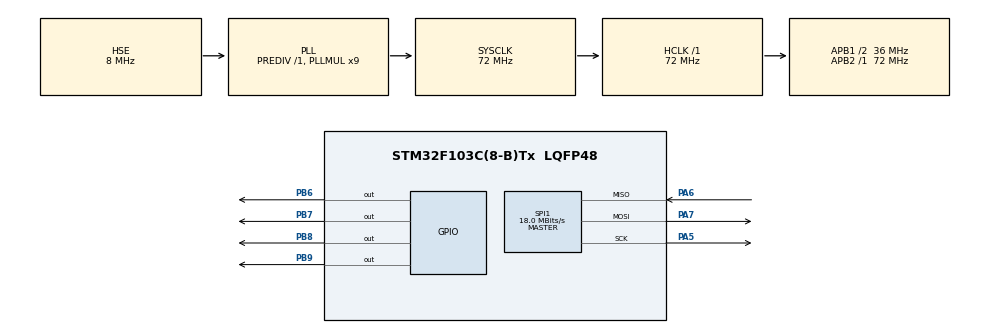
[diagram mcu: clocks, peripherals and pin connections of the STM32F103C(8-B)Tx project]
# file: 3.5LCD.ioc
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Mcu.Family=STM32F1
Mcu.Name=STM32F103C(8-B)Tx
Mcu.Package=LQFP48
NVIC.PriorityGroup=NVIC_PRIORITYGROUP_4
PA13.Mode=Serial_Wire
PA13.Signal=SYS_JTMS-SWDIO
PA14.Mode=Serial_Wire
PA14.Signal=SYS_JTCK-SWCLK
PA5.Mode=Full_Duplex_Master
PA5.Signal=SPI1_SCK
PA6.Mode=Full_Duplex_Master
PA6.Signal=SPI1_MISO
PA7.Mode=Full_Duplex_Master
PA7.Signal=SPI1_MOSI
PB6.GPIO_Speed=GPIO_SPEED_FREQ_HIGH
PB6.Signal=GPIO_Output
PB7.GPIO_Speed=GPIO_SPEED_FREQ_HIGH
PB7.Signal=GPIO_Output
PB8.GPIO_Speed=GPIO_SPEED_FREQ_HIGH
PB8.PinState=GPIO_PIN_RESET
PB8.Signal=GPIO_Output
PB9.GPIO_Speed=GPIO_SPEED_FREQ_HIGH
PB9.PinState=GPIO_PIN_SET
PB9.Signal=GPIO_Output
PD0-OSC_IN.Mode=HSE-External-Oscillator
PD0-OSC_IN.Signal=RCC_OSC_IN
PD1-OSC_OUT.Mode=HSE-External-Oscillator
PD1-OSC_OUT.Signal=RCC_OSC_OUT
ProjectManager.HeapSize=0x200
ProjectManager.StackSize=0x400
ProjectManager.TargetToolchain=MDK-ARM V5.32
RCC.AHBFreq_Value=72000000
RCC.APB1CLKDivider=RCC_HCLK_DIV2
RCC.APB1Freq_Value=36000000
RCC.APB1TimFreq_Value=72000000
RCC.APB2Freq_Value=72000000
RCC.APB2TimFreq_Value=72000000
RCC.HCLKFreq_Value=72000000
RCC.PLLMUL=RCC_PLL_MUL9
RCC.PLLSourceVirtual=RCC_PLLSOURCE_HSE
RCC.SYSCLKFreq_VALUE=72000000
RCC.SYSCLKSource=RCC_SYSCLKSOURCE_PLLCLK
RCC.USBFreq_Value=72000000
SPI1.BaudRatePrescaler=SPI_BAUDRATEPRESCALER_4
SPI1.CLKPhase=SPI_PHASE_2EDGE
SPI1.CLKPolarity=SPI_POLARITY_HIGH
SPI1.CRCCalculation=SPI_CRCCALCULATION_DISABLE
SPI1.CalculateBaudRate=18.0 MBits/s
SPI1.DataSize=SPI_DATASIZE_16BIT
SPI1.Direction=SPI_DIRECTION_2LINES
SPI1.Mode=SPI_MODE_MASTER
SPI1.VirtualType=VM_MASTER
board=custom

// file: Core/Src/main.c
/* USER CODE BEGIN Header */
/**
  ******************************************************************************
  * @file           : main.c
  * @brief          : Main program body
  ******************************************************************************
  * @attention
  *
  * Copyright (c) 2025 STMicroelectronics.
  * All rights reserved.
  *
  * This software is licensed under terms that can be found in the LICENSE file
  * in the root directory of this software component.
  * If no LICENSE file comes with this software, it is provided AS-IS.
  *
  ******************************************************************************
  */
/* USER CODE END Header */
#include "main.h"
#include "spi.h"
#include "gpio.h"

/* USER CODE BEGIN Includes */
#include "lcd.h"
/* USER CODE END Includes */

/* USER CODE BEGIN PTD */
uint8_t BMP[] =
{
/*--  ������һ��ͼ��C:\Users\Administrator\Desktop\22.bmp  --*/
/*--  ���x�߶�=240x160  --*/
0x00,0x00,0x00,0x00,0x00,0x00,0x00,0x00,0x00,0x00,0x00,0x00,0x00,0x00,0x00,0x00,
0x00,0x00,0x00,0x00,0x00,0x00,0x00,0x00,0x00,0x00,0x00,0x00,0x00,0x00,0x00,0x00,
0x00,0x00,0x00,0x00,0x00,0x00,0x00,0x00,0x00,0x00,0x00,0x00,0x00,0x00,0x00,0x00,
0x00,0x00,0x00,0x00,0x00,0x00,0x00,0x00,0x00,0x00,0x00,0x00,0x00,0x00,0x00,0x00,
0x00,0x00,0x00,0x00,0x00,0x00,0x00,0x00,0x00,0x00,0x00,0x00,0x00,0x00,0x00,0x00,
0x00,0x00,0x00,0x00,0x00,0x00,0x00,0x00,0x00,0x00,0x00,0x00,0x00,0x00,0x00,0x00,
0x00,0x00,0x00,0x00,0x00,0x00,0x00,0x00,0x00,0x00,0x00,0x00,0x00,0x00,0x00,0x00,
0x00,0x00,0x00,0x00,0x00,0x00,0x00,0x00,0x00,0x00,0x00,0x00,0x00,0x00,0x00,0x00,
0x00,0x00,0x00,0x00,0x00,0x00,0x00,0x00,0x00,0x00,0x00,0x00,0x00,0x00,0x00,0x00,
0x00,0x00,0x00,0x00,0x00,0x00,0x00,0x00,0x00,0x00,0x00,0x00,0x00,0x00,0x00,0x00,
0x00,0x00,0x00,0x00,0x00,0x00,0x00,0x00,0x00,0x00,0x00,0x00,0x00,0x00,0x00,0x00,
0x00,0x00,0x00,0x00,0x00,0x00,0x00,0x00,0x00,0x00,0x00,0x00,0x00,0x00,0x00,0x00,
0x00,0x00,0x00,0x00,0x00,0x00,0x00,0x00,0x00,0x00,0x00,0x00,0x00,0x00,0x00,0x00,
0x00,0x00,0x00,0x00,0x00,0x00,0x00,0x00,0x00,0x00,0x00,0x00,0x00,0x00,0x00,0x00,
0x00,0x00,0x00,0x00,0x00,0x00,0x00,0x00,0x00,0x00,0x00,0x00,0x00,0x00,0x00,0x00,
0x00,0x00,0x00,0x00,0x00,0x00,0x00,0x00,0x00,0x00,0x00,0x00,0x00,0x00,0x00,0x00,
0x00,0x00,0x00,0x00,0x00,0x00,0x00,0x00,0x00,0x00,0x00,0x00,0x00,0x00,0x00,0x00,
0x00,0x00,0x00,0x00,0x00,0x00,0x00,0x00,0x00,0x00,0x00,0x00,0x00,0x00,0x00,0x00,
0x00,0x00,0x00,0x00,0x00,0x00,0x00,0x00,0x00,0x00,0x00,0x00,0x00,0x00,0x00,0x00,
0x00,0x00,0x00,0x00,0x00,0x00,0x00,0x00,0x00,0x00,0x00,0x00,0x00,0x00,0x00,0x00,
0x00,0x00,0x00,0x00,0x00,0x00,0x00,0x00,0x00,0x00,0x00,0x00,0x00,0x00,0x00,0x00,
0x00,0x00,0x00,0x00,0x00,0x00,0x00,0x00,0x00,0x00,0x00,0x00,0x00,0x00,0x00,0x00,
0x00,0x00,0x00,0x00,0x00,0x00,0x00,0x00,0x00,0x00,0x00,0x00,0x00,0x00,0x00,0x00,
0x00,0x00,0x00,0x00,0x00,0x00,0x00,0x00,0x00,0x00,0x00,0x00,0x00,0x00,0x00,0x00,
0x00,0x00,0x00,0x00,0x00,0x00,0x00,0x00,0x00,0x00,0x00,0x00,0x00,0x00,0x00,0x00,
0x00,0x00,0x00,0x00,0x00,0x00,0x00,0x00,0x00,0x00,0x00,0x00,0x00,0x00,0x00,0x00,
0x00,0x00,0x00,0x00,0x00,0x00,0x00,0x00,0x00,0x00,0x00,0x00,0x00,0x00,0x00,0x00,
0x00,0x00,0x00,0x00,0x00,0x00,0x00,0x00,0x00,0x00,0x00,0x00,0x00,0x00,0x00,0x00,
0x00,0x00,0x00,0x00,0x00,0x00,0x00,0x00,0x00,0x00,0x00,0x00,0x00,0x00,0x00,0x00,
0x00,0x00,0x00,0x00,0x00,0x00,0x00,0x00,0x00,0x00,0x00,0x00,0x00,0x00,0x00,0x00,
0x00,0x00,0x00,0x00,0x00,0x00,0x00,0x00,0x00,0x00,0x00,0x00,0x00,0x00,0x00,0x00,
0x00,0x00,0x00,0x00,0x00,0x00,0x00,0x00,0x00,0x00,0x00,0x00,0x00,0x00,0x00,0x00,
0x00,0x00,0x00,0x00,0x00,0x00,0x00,0x00,0x00,0x00,0x00,0x00,0x00,0x00,0x00,0x00,
0x00,0x00,0x00,0x00,0x00,0x00,0x00,0x00,0x00,0x00,0x00,0x00,0x00,0x00,0x00,0x00,
0x00,0x00,0x00,0x00,0x00,0x00,0x00,0x00,0x00,0x00,0x00,0x00,0x00,0x00,0x00,0x00,
0x00,0x00,0x00,0x00,0x00,0x00,0x00,0x00,0x00,0x00,0x00,0x00,0x00,0x00,0x00,0x00,
0x00,0x00,0x00,0x00,0x00,0x00,0x00,0x00,0x00,0x00,0x00,0x00,0x00,0x00,0x00,0x00,
0x00,0x00,0x00,0x00,0x00,0x00,0x00,0x00,0x00,0x00,0x00,0x00,0x00,0x00,0x00,0x00,
0x00,0x00,0x00,0x00,0x00,0x00,0x00,0x00,0x00,0x00,0x00,0x00,0x00,0x00,0x00,0x00,
0x00,0x00,0x00,0x00,0x00,0x00,0x00,0x00,0x00,0x00,0x00,0x00,0x00,0x00,0x00,0x00,
0x00,0x00,0x00,0x00,0x00,0x00,0x00,0x00,0x00,0x00,0x00,0x00,0x00,0x00,0x00,0x00,
0x00,0x00,0x00,0x00,0x00,0x00,0x00,0x00,0x00,0x00,0x00,0x00,0x00,0x00,0x00,0x00,
0x00,0x00,0x00,0x00,0x00,0x00,0x00,0x00,0x00,0x00,0x00,0x00,0x00,0x00,0x00,0x00,
0x00,0x00,0x00,0x00,0x00,0x00,0x00,0x00,0x00,0x00,0x00,0x00,0x00,0x00,0x00,0x00,
0x00,0x00,0x00,0x00,0x00,0x00,0x00,0x00,0x00,0x00,0x00,0x00,0x00,0x00,0x00,0x00,
0x00,0x00,0x00,0x00,0x00,0x00,0x00,0x00,0x00,0x00,0x00,0x00,0x00,0x00,0x00,0x00,
0x00,0x00,0x00,0x00,0x00,0x00,0x00,0x00,0x00,0x00,0x00,0x00,0x00,0x00,0x00,0x00,
0x00,0x00,0x00,0x00,0x00,0x00,0x00,0x00,0x00,0x00,0x00,0x00,0x00,0x00,0x00,0x00,
0x00,0x00,0x00,0x00,0x00,0x00,0x00,0x00,0x00,0x00,0x00,0x00,0x00,0x00,0x00,0x00,
0x00,0x00,0x00,0x00,0x00,0x00,0x00,0x00,0x00,0x00,0x00,0x00,0x00,0x00,0x00,0x00,
0x00,0x00,0x00,0x00,0x00,0x00,0x00,0x00,0x00,0x00,0x00,0x00,0x00,0x00,0x00,0x00,
0x00,0x00,0x00,0x00,0x00,0x00,0x00,0x00,0x00,0x00,0x00,0x00,0x00,0x00,0x00,0x00,
0x00,0x00,0x00,0x00,0x00,0x00,0x00,0x00,0x00,0x00,0x00,0x00,0x00,0x00,0x00,0x00,
0x00,0x00,0x00,0x00,0x00,0x00,0x00,0x00,0x00,0x00,0x00,0x00,0x00,0x00,0x00,0x00,
0x00,0x00,0x00,0x00,0x00,0x00,0x00,0x00,0x00,0x00,0x00,0x00,0x00,0x00,0x00,0x00,
0x00,0x00,0x00,0x00,0x00,0x00,0x00,0x00,0x00,0x00,0x00,0x00,0x00,0x00,0x00,0x00,
0x00,0x00,0x00,0x00,0x00,0x00,0x00,0x00,0x00,0x00,0x00,0x00,0x00,0x00,0x00,0x00,
0x00,0x00,0x00,0x00,0x00,0x00,0x00,0x00,0x00,0x00,0x00,0x00,0x00,0x00,0x00,0x00,
0x00,0x00,0x00,0x00,0x00,0x00,0x00,0x00,0x00,0x00,0x00,0x00,0x00,0x00,0x00,0x00,
0x00,0x00,0x00,0x00,0x00,0x00,0x00,0x00,0x00,0x00,0x00,0x00,0x00,0x00,0x00,0x00,
0x00,0x00,0x00,0x00,0x00,0x00,0x00,0x00,0x00,0x00,0x00,0x00,0x00,0x00,0x00,0x00,
0x00,0x00,0x00,0x00,0x00,0x00,0x00,0x00,0x00,0x00,0x00,0x00,0x00,0x00,0x00,0x00,
0x00,0x00,0x00,0x00,0x00,0x00,0x00,0x00,0x00,0x00,0x00,0x00,0x00,0x00,0x00,0x00,
0x00,0x00,0x00,0x00,0x03,0xFF,0xC0,0x00,0x00,0x00,0x00,0x00,0x00,0x00,0x00,0x00,
0x00,0x00,0x00,0x0E,0x00,0x00,0x00,0x00,0x00,0x00,0x03,0xFF,0x00,0x03,0x80,0x00,
0x00,0x00,0x03,0xFF,0xC1,0xC0,0x00,0x00,0x00,0x00,0x00,0x00,0x00,0x00,0x00,0x00,
0x00,0x1F,0x00,0x00,0x00,0x00,0x00,0x00,0x03,0xFF,0x80,0x0F,0x80,0x00,0x00,0x00,
0x03,0xFF,0xC3,0xC0,0x00,0x00,0x00,0x00,0x00,0x00,0x00,0x00,0x00,0x00,0x00,0x3F,
0xC0,0x00,0x00,0x00,0x00,0x00,0x03,0xFF,0x80,0x1F,0xC0,0x00,0x00,0x00,0x03,0xFF,
0xCF,0xE0,0x00,0x00,0x00,0x00,0x00,0x00,0x00,0x00,0x00,0x00,0x00,0x7F,0xE0,0x7F,
0xFF,0xFF,0xFF,0x00,0x03,0xFF,0x80,0x7F,0xE0,0x00,0x00,0x00,0x03,0xFF,0xDF,0xF0,
0x00,0x00,0x00,0x00,0x00,0x00,0x00,0x00,0x00,0x00,0x00,0x7F,0xF0,0x7F,0xFF,0xFF,
0xFF,0x00,0x03,0xFF,0x81,0xFF,0xF0,0x00,0x00,0x00,0x03,0xFF,0xFF,0xF8,0x00,0x00,
0x00,0x00,0x00,0x00,0x00,0x00,0x00,0x00,0x00,0xFF,0xF8,0x7F,0xFF,0xFF,0xFF,0x00,
0x03,0xFF,0x81,0xFF,0xF0,0x00,0x00,0x00,0x03,0xFF,0xFF,0xFC,0x00,0x00,0x00,0x00,
0x00,0x00,0x00,0x00,0x00,0x00,0x01,0xFF,0xFE,0x7F,0xFF,0xFF,0xFF,0x3F,0xF3,0xFF,
0x81,0xFF,0xF8,0x00,0x00,0x00,0x03,0xFF,0xFF,0xFE,0x00,0x00,0x00,0x00,0x00,0x00,
0x00,0x00,0x00,0x00,0x01,0xFF,0xFF,0x7F,0xFF,0xFF,0xFF,0x3F,0xF3,0xFF,0x80,0xFF,
0xFC,0x00,0x00,0x00,0x03,0xFF,0xDF,0xFF,0x00,0x00,0x00,0x00,0x00,0x00,0x00,0x00,
0x00,0x00,0x00,0xFF,0xFF,0xFF,0xFF,0xFF,0xFF,0x3F,0xF3,0xFF,0x80,0x7F,0xFC,0x00,
0x00,0x00,0x03,0xFF,0xCF,0xFF,0x80,0x00,0x00,0x00,0x00,0x00,0x00,0x00,0x00,0x00,
0x00,0x7F,0xFF,0xFF,0xFF,0xFF,0xFF,0x3F,0xF3,0xFF,0x80,0x7F,0xFE,0x00,0x00,0x00,
0x03,0xFF,0xC7,0xFF,0x80,0x00,0x00,0x00,0x00,0x00,0x00,0x00,0x00,0x00,0x00,0x3F,
0xFF,0xFF,0xFF,0xFF,0xFF,0x3F,0xF3,0xFF,0x80,0x3F,0xFF,0x00,0x00,0x00,0x03,0xFF,
0xC7,0xFF,0x80,0x00,0x00,0x00,0x00,0x00,0x00,0x00,0x00,0x00,0x00,0x1F,0xFF,0xFF,
0xFF,0xFF,0xFF,0x3F,0xF3,0xFF,0x80,0x1F,0xFF,0x00,0x00,0x00,0x03,0xFF,0xC3,0xFF,
0x00,0x00,0x00,0x00,0x00,0x00,0x00,0x00,0x00,0x00,0x00,0x0F,0xFF,0x7F,0xC0,0x01,
0xFF,0x3F,0xF3,0xFF,0x80,0x1F,0xFF,0x80,0x00,0x00,0x03,0xFF,0xC1,0xFE,0x00,0x00,
0x00,0x00,0x00,0x00,0x00,0x00,0x00,0x00,0x00,0x07,0xFE,0x7F,0xC0,0x01,0xFF,0x3F,
0xF3,0xFF,0x80,0x0F,0xFF,0xC0,0x00,0x00,0x03,0xFF,0xC0,0xF8,0x00,0x00,0x00,0x00,
0x00,0x00,0x00,0x00,0x00,0x00,0x00,0x03,0xFC,0x7F,0xC0,0x01,0xFF,0x3F,0xF3,0xFF,
0x80,0x0F,0xFF,0xFF,0xFF,0xFF,0xFF,0xFF,0xFF,0xFF,0xE0,0x00,0x00,0x00,0x00,0x00,
0x00,0x00,0x00,0x00,0x00,0x01,0xF8,0x7F,0xC0,0x01,0xFF,0x3F,0xF3,0xFF,0x80,0x07,
0xFF,0xBF,0xFF,0xFF,0xFF,0xFF,0xFF,0xFF,0xE0,0x00,0x00,0x00,0x00,0x00,0x00,0x00,
0x00,0x00,0x00,0x00,0xF0,0x7F,0xC0,0x01,0xFF,0x3F,0xF3,0xFF,0x80,0x03,0xFE,0x3F,
0xFF,0xFF,0xFF,0xFF,0xFF,0xFF,0xE0,0x00,0x00,0x00,0x00,0x00,0x00,0x00,0x00,0x00,
0x00,0x00,0x60,0x7F,0xCF,0xF9,0xFF,0x3F,0xF3,0xFF,0x80,0x03,0xFC,0x3F,0xFF,0xFF,
0xFF,0xFF,0xFF,0xFF,0xE0,0x00,0x00,0x00,0x00,0x00,0x00,0x00,0x00,0x00,0x00,0x00,
0x00,0x7F,0xCF,0xF9,0xFF,0x3F,0xF3,0xFF,0x80,0x01,0xF0,0x3F,0xFF,0xFF,0xFF,0xFF,
0xFF,0xFF,0xE0,0x00,0x00,0x00,0x00,0x00,0x00,0x00,0x00,0x00,0x00,0x00,0x00,0x7F,
0xCF,0xF9,0xFF,0x3F,0xF3,0xFF,0x80,0x01,0xC0,0x3F,0xFF,0xFF,0xFF,0xFF,0xFF,0xFF,
0xE0,0x00,0x00,0x00,0x00,0x00,0x00,0x00,0x00,0x00,0x00,0x00,0x00,0x7F,0xCF,0xF9,
0xFF,0x3F,0xF3,0xFF,0x80,0x00,0x00,0x3F,0xFF,0xFF,0xFF,0xFF,0xFF,0xFF,0xE0,0x00,
0x00,0x00,0x00,0x00,0x00,0x00,0x00,0x00,0x00,0x3C,0x00,0x7F,0xCF,0xF9,0xFF,0x3F,
0xF3,0xFF,0x80,0x00,0x00,0x3F,0xFF,0xFF,0xFF,0xFF,0xFF,0xFF,0xE0,0x00,0x00,0x00,
0x00,0x00,0x00,0x00,0x00,0x00,0x00,0x7E,0x00,0x7F,0xCF,0xF9,0xFF,0x3F,0xF3,0xFF,
0x80,0x00,0x00,0x3F,0xFF,0xFF,0xFF,0xFF,0xFF,0xFF,0xE0,0x00,0x00,0x00,0x00,0x00,
0x00,0x00,0x00,0x00,0x00,0xFF,0x00,0x7F,0xCF,0xF9,0xFF,0x3F,0xF3,0xFF,0x80,0x00,
0x00,0x3F,0xFF,0xFF,0xFF,0xFF,0xFF,0xFF,0xE0,0x00,0x00,0x00,0x00,0x00,0x00,0x00,
0x00,0x00,0x01,0xFF,0x80,0x7F,0xCF,0xF9,0xFF,0x3F,0xF3,0xFF,0x8F,0xFF,0xFE,0x3F,
0xFF,0xFF,0xFF,0xFF,0xFF,0xFF,0xE0,0x00,0x00,0x00,0x00,0x00,0x00,0x00,0x00,0x00,
0x01,0xFF,0xE0,0x7F,0xCF,0xF9,0xFF,0x3F,0xF3,0xFF,0x8F,0xFF,0xFE,0x00,0x00,0x00,
0x01,0xFF,0xE0,0x00,0x00,0x00,0x00,0x00,0x00,0x00,0x00,0x00,0x00,0x00,0x03,0xFF,
0xF0,0x7F,0xCF,0xF9,0xFF,0x3F,0xF3,0xFF,0x8F,0xFF,0xFE,0x00,0x00,0x00,0x01,0xFF,
0xE0,0x00,0x00,0x00,0x00,0x00,0x00,0x00,0x00,0x00,0x00,0x00,0x07,0xFF,0xF8,0x7F,
0xCF,0xF9,0xFF,0x3F,0xF3,0xFF,0x8F,0xFF,0xFE,0x00,0x00,0x00,0x01,0xFF,0xE0,0x00,
0x00,0x00,0x00,0x00,0x00,0x00,0x00,0x00,0x00,0x00,0x07,0xFF,0xFC,0x7F,0xCF,0xF9,
0xFF,0x3F,0xF3,0xFF,0x8F,0xFF,0xFE,0x00,0x00,0x00,0x01,0xFF,0xE0,0x00,0x00,0x00,
0x00,0x00,0x00,0x00,0x00,0x00,0x00,0x00,0x03,0xFF,0xFE,0x7F,0xCF,0xF9,0xFF,0x3F,
0xF3,0xFF,0x8F,0xFF,0xFE,0x00,0x00,0x00,0x01,0xFF,0xE0,0x00,0x00,0x00,0x00,0x00,
0x00,0x00,0x00,0x00,0x00,0x00,0x01,0xFF,0xFF,0x7F,0xCF,0xF9,0xFF,0x3F,0xF3,0xFF,
0x8F,0xFF,0xFE,0x00,0x00,0x00,0x01,0xFF,0xE0,0x00,0x00,0x00,0x00,0x00,0x00,0x00,
0x00,0x00,0x00,0x00,0x00,0xFF,0xFF,0x7F,0xCF,0xF9,0xFF,0x3F,0xF3,0xFF,0x8F,0xFF,
0xFE,0x00,0x00,0x00,0x01,0xFF,0xE0,0x00,0x00,0x00,0x00,0x00,0x00,0x00,0x00,0x00,
0x00,0x00,0x00,0x7F,0xFE,0x7F,0xCF,0xF9,0xFF,0x3F,0xF3,0xFF,0x8F,0xFF,0xFE,0x00,
0x00,0x00,0x01,0xFF,0xE0,0x00,0x00,0x00,0x00,0x00,0x00,0x00,0x00,0x00,0x00,0x00,
0x00,0x3F,0xFC,0x7F,0xCF,0xF9,0xFF,0x3F,0xF3,0xFF,0x8F,0xFF,0xFE,0x1F,0xFF,0xFF,
0xFD,0xFF,0xE0,0x00,0x00,0x00,0x00,0x00,0x00,0x00,0x00,0x00,0x00,0x00,0x00,0x1F,
0xF8,0x7F,0xCF,0xF9,0xFF,0x3F,0xF3,0xFF,0x87,0xFF,0xFE,0x1F,0xFF,0xFF,0xFD,0xFF,
0xE0,0x00,0x00,0x00,0x00,0x00,0x00,0x00,0x00,0x00,0x00,0x00,0x00,0x0F,0xF0,0x7F,
0xCF,0xF9,0xFF,0x3F,0xF3,0xFF,0x80,0x1F,0xFE,0x1F,0xFF,0xFF,0xFD,0xFF,0xE0,0x00,
0x00,0x00,0x00,0x00,0x00,0x00,0x00,0x00,0x00,0x00,0x00,0x07,0xF0,0x7F,0xCF,0xF9,
0xFF,0x3F,0xF3,0xFF,0x80,0x1F,0xFE,0x1F,0xFF,0xFF,0xFD,0xFF,0xE0,0x00,0x00,0x00,
0x00,0x00,0x00,0x00,0x00,0x00,0x00,0x00,0x00,0x03,0xE0,0x7F,0xCF,0xF9,0xFF,0x3F,
0xF3,0xFF,0x80,0x1F,0xFE,0x1F,0xFF,0xFF,0xFD,0xFF,0xE0,0x00,0x00,0x00,0x00,0x00,
0x00,0x00,0x00,0x00,0x00,0x00,0x00,0x01,0xC0,0x7F,0xCF,0xF9,0xFF,0x3F,0xF3,0xFF,
0x80,0x1F,0xFE,0x1F,0xFF,0xFF,0xFD,0xFF,0xE0,0x00,0x00,0x00,0x00,0x00,0x00,0x00,
0x00,0x00,0x00,0x00,0x00,0x00,0x00,0x7F,0xCF,0xF9,0xFF,0x3F,0xF3,0xFF,0x80,0x1F,
0xFE,0x1F,0xFF,0xFF,0xFD,0xFF,0xE0,0x00,0x00,0x00,0x00,0x00,0x00,0x00,0x00,0x00,
0x00,0x00,0x00,0x00,0x00,0x7F,0xCF,0xF9,0xFF,0x3F,0xF3,0xFF,0x80,0x1F,0xFE,0x1F,
0xFF,0xFF,0xFD,0xFF,0xE0,0x00,0x00,0x00,0x00,0x00,0x00,0x00,0x00,0x00,0x00,0x00,
0x00,0x00,0x00,0x7F,0xCF,0xF9,0xFF,0x3F,0xF3,0xFF,0x80,0x1F,0xFE,0x1F,0xFF,0xFF,
0xFC,0xFF,0xF0,0x00,0x00,0x00,0x00,0x00,0x00,0x00,0x00,0x00,0x00,0x00,0x00,0x00,
0x00,0x7F,0xCF,0xF9,0xFF,0x3F,0xF3,0xFF,0x80,0x1F,0xFE,0x1F,0xFF,0xFF,0xFC,0xFF,
0xF0,0x00,0x00,0x00,0x00,0x00,0x00,0x00,0x00,0x00,0x00,0x00,0x00,0x07,0x00,0x7F,
0xCF,0xF1,0xFF,0x3F,0xF3,0xFF,0x80,0x1F,0xFE,0x0F,0xFF,0xFF,0xF8,0xFF,0xF0,0x00,
0x00,0x00,0x00,0x00,0x00,0x00,0x00,0x00,0x00,0x00,0x00,0x07,0xE0,0x7F,0xDF,0xF1,
0xFF,0x3F,0xF3,0xFF,0x80,0x1F,0xFE,0x00,0x1F,0xFC,0x00,0xFF,0xF0,0x00,0x00,0x00,
0x00,0x00,0x00,0x00,0x00,0x00,0x00,0x00,0x00,0x07,0xFC,0x7F,0xDF,0xF1,0xFF,0x3F,
0xF3,0xFF,0x80,0x1F,0xFE,0x00,0x1F,0xFC,0x00,0xFF,0xF0,0x00,0x00,0x00,0x00,0x00,
0x00,0x00,0x00,0x00,0x00,0x00,0x00,0x07,0xFF,0x7F,0xDF,0xF1,0xFF,0x3F,0xF3,0xFF,
0x80,0x1F,0xFE,0x00,0x1F,0xFC,0x00,0xFF,0xF0,0x00,0x00,0x00,0x00,0x00,0x00,0x00,
0x00,0x00,0x00,0x00,0x00,0x0F,0xFF,0x7F,0xDF,0xF1,0xFF,0x3F,0xF3,0xFF,0x80,0x1F,
0xFE,0x00,0x1F,0xFC,0x00,0xFF,0xF0,0x00,0x00,0x00,0x00,0x00,0x00,0x00,0x00,0x00,
0x00,0x00,0x00,0x0F,0xFF,0x7F,0xDF,0xF1,0xFF,0x3F,0xF3,0xFF,0x80,0x1F,0xFE,0x00,
0x1F,0xFC,0x00,0xFF,0xF0,0x00,0x00,0x00,0x00,0x00,0x00,0x00,0x00,0x00,0x00,0x00,
0x00,0x0F,0xFF,0x7F,0xFF,0xF1,0xFF,0x3F,0xF3,0xFF,0x80,0x1F,0xFE,0x00,0x1F,0xFC,
0x00,0xFF,0xF0,0x00,0x00,0x00,0x00,0x00,0x00,0x00,0x00,0x00,0x00,0x00,0x00,0x0F,
0xFF,0x7F,0xFF,0xF1,0xFF,0x3F,0xF3,0xFF,0x80,0x1F,0xFE,0x00,0x1F,0xFC,0x00,0xFF,
0xF8,0x00,0x00,0x00,0x00,0x00,0x00,0x00,0x00,0x00,0x00,0x00,0x00,0x0F,0xFE,0x7F,
0xFF,0xF1,0xFF,0x3F,0xF3,0xFF,0x80,0x1F,0xFE,0x00,0x1F,0xFC,0x00,0xFF,0xF8,0x00,
0x00,0x00,0x00,0x00,0x00,0x00,0x00,0x00,0x00,0x00,0x00,0x1F,0xFE,0x7F,0xFF,0xE0,
0x00,0x3F,0xF3,0xFF,0x80,0x1F,0xFE,0x0C,0x1F,0xFC,0x00,0x7F,0xF8,0x78,0x00,0x00,
0x00,0x00,0x00,0x00,0x00,0x00,0x00,0x00,0x00,0x1F,0xFE,0x00,0x7F,0xE0,0x00,0x3F,
0xF3,0xFF,0x80,0x1F,0xFE,0x3C,0x1F,0xFC,0x00,0x7F,0xF8,0x7E,0x00,0x00,0x00,0x00,
0x00,0x00,0x00,0x00,0x00,0x00,0x00,0x1F,0xFE,0x00,0x7F,0xE6,0x00,0x3F,0xF3,0xFF,
0x80,0x1F,0xFE,0x7E,0x1F,0xFC,0x00,0x7F,0xF8,0x7F,0xC0,0x00,0x00,0x00,0x00,0x00,
0x00,0x00,0x00,0x00,0x00,0x1F,0xFC,0x00,0xFF,0xEF,0x00,0x3F,0xF3,0xFF,0x80,0x1F,
0xFE,0xFE,0x1F,0xFC,0x00,0x7F,0xF8,0x7F,0xF0,0x00,0x00,0x00,0x00,0x00,0x00,0x00,
0x00,0x00,0x00,0x3F,0xFC,0x00,0xFF,0xFF,0x80,0x3F,0xF3,0xFF,0x80,0x1F,0xFF,0xFE,
0x1F,0xFC,0x00,0x7F,0xFC,0x7F,0xF0,0x00,0x00,0x00,0x00,0x00,0x00,0x00,0x00,0x00,
0x00,0x3F,0xFC,0x01,0xFF,0xFF,0xC0,0x3F,0xF3,0xFF,0x80,0x1F,0xFF,0xFE,0x1F,0xFC,
0x00,0x7F,0xFC,0x7F,0xF0,0x00,0x00,0x00,0x00,0x00,0x00,0x00,0x00,0x00,0x00,0x3F,
0xFC,0x03,0xFF,0xFF,0xE0,0x3F,0xF3,0xFF,0x80,0x1F,0xFF,0xFE,0x1F,0xFC,0x7F,0x7F,
0xFC,0x7F,0xF0,0x00,0x00,0x00,0x00,0x00,0x00,0x00,0x00,0x00,0x00,0x3F,0xF8,0x03,
0xFF,0xFF,0xF0,0x00,0x03,0xFF,0x80,0x1F,0xFF,0xFE,0x1F,0xFF,0xFF,0x3F,0xFC,0x7F,
0xE0,0x00,0x00,0x00,0x00,0x00,0x00,0x00,0x00,0x00,0x00,0x7F,0xF8,0x07,0xFF,0xFF,
0xF8,0x00,0x03,0xFF,0x80,0x1F,0xFF,0xFE,0x1F,0xFF,0xFF,0x3F,0xFC,0xFF,0xE0,0x00,
0x00,0x00,0x00,0x00,0x00,0x00,0x00,0x00,0x00,0x7F,0xF8,0x0F,0xFF,0x7F,0xFC,0x00,
0x03,0xFF,0x80,0x1F,0xFF,0xFF,0xFF,0xFF,0xFF,0x3F,0xFE,0xFF,0xE0,0x00,0x00,0x00,
0x00,0x00,0x00,0x00,0x00,0x00,0x00,0x7F,0xF8,0x1F,0xFF,0x3F,0xFE,0x00,0x03,0xFF,
0x80,0x1F,0xFF,0xFF,0xFF,0xFF,0xFF,0x3F,0xFE,0xFF,0xE0,0x00,0x00,0x00,0x00,0x00,
0x00,0x00,0x00,0x00,0x00,0x7F,0xF0,0x3F,0xFE,0x3F,0xFE,0x00,0x07,0xFF,0x80,0x1F,
0xFF,0xFF,0xFF,0xFF,0xFF,0x1F,0xFE,0xFF,0xE0,0x00,0x00,0x00,0x00,0x00,0x00,0x00,
0x00,0x00,0x00,0xFF,0xF0,0x7F,0xFE,0x1F,0xFF,0x3F,0xFF,0xFF,0x80,0x1F,0xFF,0xFF,
0xFF,0xFF,0xFF,0x1F,0xFF,0xFF,0xE0,0x00,0x00,0x00,0x00,0x00,0x00,0x00,0x00,0x00,
0x00,0xFF,0xF0,0xFF,0xFC,0x0F,0xFF,0x9F,0xFF,0xFF,0x80,0x1F,0xFF,0xFF,0xFF,0xFF,
0xFF,0x1F,0xFF,0xFF,0xC0,0x00,0x00,0x00,0x00,0x00,0x00,0x00,0x00,0x00,0x00,0xFF,
0xF3,0xFF,0xF8,0x07,0xFF,0xDF,0xFF,0xFF,0x80,0x3F,0xFF,0xFF,0xFF,0xFF,0xFF,0x1F,
0xFF,0xFF,0xC0,0x00,0x00,0x00,0x00,0x00,0x00,0x00,0x00,0x00,0x01,0xFF,0xE7,0xFF,
0xF8,0x07,0xFF,0xFF,0xFF,0xFF,0x00,0x3F,0xFF,0xFF,0xFF,0xFF,0xFF,0x0F,0xFF,0xFF,
0xC0,0x00,0x00,0x00,0x00,0x00,0x00,0x00,0x00,0x00,0x01,0xFF,0xE7,0xFF,0xF0,0x03,
0xFF,0xDF,0xFF,0xFF,0x00,0x7F,0xFF,0x9F,0xFF,0xFF,0xFF,0x0F,0xFF,0xFF,0xC0,0x00,
0x00,0x00,0x00,0x00,0x00,0x00,0x00,0x00,0x01,0xFF,0xE3,0xFF,0xE0,0x01,0xFF,0x8F,
0xFF,0xFF,0x00,0x3F,0xFF,0x1F,0xFF,0xFF,0xFC,0x0F,0xFF,0xFF,0x80,0x00,0x00,0x00,
0x00,0x00,0x00,0x00,0x00,0x00,0x01,0xFF,0xE3,0xFF,0xC0,0x00,0xFF,0x0F,0xFF,0xFF,
0x00,0x1F,0xFE,0x1F,0xFF,0xFE,0x00,0x07,0xFF,0xFF,0x80,0x00,0x00,0x00,0x00,0x00,
0x00,0x00,0x00,0x00,0x03,0xFF,0xC1,0xFF,0xC0,0x00,0xFC,0x0F,0xFF,0xFE,0x00,0x1F,
0xF8,0x1F,0xFF,0x80,0x00,0x07,0xFF,0xFF,0x00,0x00,0x00,0x00,0x00,0x00,0x00,0x00,
0x00,0x00,0x03,0xFF,0xC0,0xFF,0x80,0x00,0x78,0x0F,0xFF,0xFC,0x00,0x0F,0xF0,0x0F,
0xE0,0x00,0x00,0x03,0xFF,0xFF,0x00,0x00,0x00,0x00,0x00,0x00,0x00,0x00,0x00,0x00,
0x01,0xFF,0xC0,0x7F,0x00,0x00,0x30,0x0F,0xFF,0xF8,0x00,0x07,0xE0,0x00,0x00,0x00,
0x00,0x01,0xFF,0xFE,0x00,0x00,0x00,0x00,0x00,0x00,0x00,0x00,0x00,0x00,0x00,0x3F,
0xC0,0x3E,0x00,0x00,0x00,0x07,0xFF,0xF0,0x00,0x03,0xC0,0x00,0x00,0x00,0x00,0x00,
0xFF,0xFC,0x00,0x00,0x00,0x00,0x00,0x00,0x00,0x00,0x00,0x00,0x00,0x07,0x80,0x3C,
0x00,0x00,0x00,0x07,0xFF,0x00,0x00,0x03,0x80,0x00,0x00,0x00,0x00,0x00,0x7F,0xF8,
0x00,0x00,0x00,0x00,0x00,0x00,0x00,0x00,0x00,0x00,0x00,0x00,0x00,0x18,0x00,0x00,
0x00,0x00,0x00,0x00,0x00,0x00,0x00,0x00,0x00,0x00,0x00,0x00,0x1F,0xE0,0x00,0x00,
0x00,0x00,0x00,0x00,0x00,0x00,0x00,0x00,0x00,0x00,0x00,0x00,0x00,0x00,0x00,0x00,
0x00,0x00,0x00,0x00,0x00,0x00,0x00,0x00,0x00,0x00,0x00,0x00,0x00,0x00,0x00,0x00,
0x00,0x00,0x00,0x00,0x00,0x00,0x00,0x00,0x00,0x00,0x00,0x00,0x00,0x00,0x00,0x00,
0x00,0x00,0x00,0x00,0x00,0x00,0x00,0x00,0x00,0x00,0x00,0x00,0x00,0x00,0x00,0x00,
0x00,0x00,0x00,0x00,0x00,0x00,0x00,0x00,0x00,0x00,0x00,0x00,0x00,0x00,0x00,0x00,
0x00,0x00,0x00,0x00,0x00,0x00,0x00,0x00,0x00,0x00,0x00,0x00,0x00,0x00,0x00,0x00,
0x00,0x00,0x00,0x00,0x00,0x00,0x00,0x00,0x00,0x00,0x00,0x00,0x00,0x00,0x00,0x00,
0x00,0x00,0x00,0x00,0x00,0x00,0x00,0x00,0x00,0x00,0x00,0x00,0x00,0x00,0x00,0x00,
0x00,0x00,0x00,0x00,0x00,0x00,0x00,0x00,0x00,0x00,0x00,0x00,0x00,0x00,0x00,0x00,
0x00,0x00,0x00,0x00,0x00,0x00,0x00,0x00,0x00,0x00,0x00,0x00,0x00,0x00,0x00,0x00,
0x00,0x00,0x00,0x00,0x00,0x00,0x00,0x00,0x00,0x00,0x00,0x00,0x00,0x00,0x00,0x00,
0x00,0x00,0x00,0x00,0x00,0x00,0x00,0x00,0x00,0x00,0x00,0x00,0x00,0x00,0x00,0x00,
0x00,0x00,0x00,0x00,0x00,0x00,0x00,0x00,0x00,0x00,0x00,0x00,0x00,0x00,0x00,0x00,
0x00,0x00,0x00,0x00,0x00,0x00,0x00,0x00,0x00,0x00,0x00,0x00,0x00,0x00,0x00,0x00,
0x00,0x00,0x00,0x00,0x00,0x00,0x00,0x00,0x00,0x00,0x00,0x00,0x00,0x00,0x00,0x00,
0x00,0x00,0x00,0x00,0x00,0x00,0x00,0x00,0x00,0x00,0x00,0x00,0x00,0x00,0x00,0x00,
0x00,0x00,0x00,0x00,0x00,0x00,0x00,0x00,0x00,0x00,0x00,0x00,0x00,0x00,0x00,0x00,
0x00,0x00,0x00,0x00,0x00,0x00,0x00,0x00,0x00,0x00,0x00,0x00,0x00,0x00,0x00,0x00,
0x00,0x00,0x00,0x00,0x00,0x00,0x00,0x00,0x00,0x00,0x00,0x00,0x00,0x00,0x00,0x00,
0x00,0x00,0x00,0x00,0x00,0x00,0x00,0x00,0x00,0x00,0x00,0x00,0x00,0x00,0x00,0x00,
0x00,0x00,0x00,0x00,0x00,0x00,0x00,0x00,0x00,0x00,0x00,0x00,0x00,0x00,0x00,0x00,
0x00,0x00,0x00,0x00,0x00,0x00,0x00,0x00,0x00,0x00,0x00,0x00,0x00,0x00,0x00,0x00,
0x00,0x00,0x00,0x00,0x00,0x00,0x00,0x00,0x00,0x00,0x00,0x00,0x00,0x00,0x00,0x00,
0x00,0x00,0x00,0x00,0x00,0x00,0x00,0x00,0x00,0x00,0x00,0x00,0x00,0x00,0x00,0x00,
0x00,0x00,0x00,0x00,0x00,0x00,0x00,0x00,0x00,0x00,0x00,0x00,0x00,0x00,0x00,0x00,
0x00,0x00,0x00,0x00,0x00,0x00,0x00,0x00,0x00,0x00,0x00,0x00,0x00,0x00,0x00,0x00,
0x00,0x00,0x00,0x00,0x00,0x00,0x00,0x00,0x00,0x00,0x00,0x00,0x00,0x00,0x00,0x00,
0x00,0x00,0x00,0x00,0x00,0x00,0x00,0x00,0x00,0x00,0x00,0x00,0x00,0x00,0x00,0x00,
0x00,0x00,0x00,0x00,0x00,0x00,0x00,0x00,0x00,0x00,0x00,0x00,0x00,0x00,0x00,0x00,
0x00,0x00,0x00,0x00,0x00,0x00,0x00,0x00,0x00,0x00,0x00,0x00,0x00,0x00,0x00,0x00,
0x00,0x00,0x00,0x00,0x00,0x00,0x00,0x00,0x00,0x00,0x00,0x00,0x00,0x00,0x00,0x00,
0x00,0x00,0x00,0x00,0x00,0x00,0x00,0x00,0x00,0x00,0x00,0x00,0x00,0x00,0x00,0x00,
0x00,0x00,0x00,0x00,0x00,0x00,0x00,0x00,0x00,0x00,0x00,0x00,0x00,0x00,0x00,0x00,
0x00,0x00,0x00,0x00,0x00,0x00,0x00,0x00,0x00,0x00,0x00,0x00,0x00,0x00,0x00,0x00,
0x00,0x00,0x00,0x00,0x00,0x00,0x00,0x00,0x00,0x00,0x00,0x00,0x00,0x00,0x00,0x00,
0x00,0x00,0x00,0x00,0x00,0x00,0x00,0x00,0x00,0x00,0x00,0x00,0x00,0x00,0x00,0x00,
0x00,0x00,0x00,0x00,0x00,0x00,0x00,0x00,0x00,0x00,0x00,0x00,0x00,0x00,0x00,0x00,
0x00,0x00,0x00,0x00,0x00,0x00,0x00,0x00,0x00,0x00,0x00,0x00,0x00,0x00,0x00,0x00,
0x00,0x00,0x00,0x00,0x00,0x00,0x00,0x00,0x00,0x00,0x00,0x00,0x00,0x00,0x00,0x00,
0x00,0x00,0x00,0x00,0x00,0x00,0x00,0x00,0x00,0x00,0x00,0x00,0x00,0x00,0x00,0x00,
0x00,0x00,0x00,0x00,0x00,0x00,0x00,0x00,0x00,0x00,0x00,0x00,0x00,0x00,0x00,0x00,
0x00,0x00,0x00,0x00,0x00,0x00,0x00,0x00,0x00,0x00,0x00,0x00,0x00,0x00,0x00,0x00,
0x00,0x00,0x00,0x00,0x00,0x00,0x00,0x00,0x00,0x00,0x00,0x00,0x00,0x00,0x00,0x00,
0x00,0x00,0x00,0x00,0x00,0x00,0x00,0x00,0x00,0x00,0x00,0x00,0x00,0x00,0x00,0x00,
0x00,0x00,0x00,0x00,0x00,0x00,0x00,0x00,0x00,0x00,0x00,0x00,0x00,0x00,0x00,0x00,
0x00,0x00,0x00,0x00,0x00,0x00,0x00,0x00,0x00,0x00,0x00,0x00,0x00,0x00,0x00,0x00,
0x00,0x00,0x00,0x00,0x00,0x00,0x00,0x00,0x00,0x00,0x00,0x00,0x00,0x00,0x00,0x00,
0x00,0x00,0x00,0x00,0x00,0x00,0x00,0x00,0x00,0x00,0x00,0x00,0x00,0x00,0x00,0x00,
0x00,0x00,0x00,0x00,0x00,0x00,0x00,0x00,0x00,0x00,0x00,0x00,0x00,0x00,0x00,0x00,
0x00,0x00,0x00,0x00,0x00,0x00,0x00,0x00,0x00,0x00,0x00,0x00,0x00,0x00,0x00,0x00,
0x00,0x00,0x00,0x00,0x00,0x00,0x00,0x00,0x00,0x00,0x00,0x00,0x00,0x00,0x00,0x00,
0x00,0x00,0x00,0x00,0x00,0x00,0x00,0x00,0x00,0x00,0x00,0x00,0x00,0x00,0x00,0x00,
0x00,0x00,0x00,0x00,0x00,0x00,0x00,0x00,0x00,0x00,0x00,0x00,0x00,0x00,0x00,0x00,
0x00,0x00,0x00,0x00,0x00,0x00,0x00,0x00,0x00,0x00,0x00,0x00,0x00,0x00,0x00,0x00,
0x00,0x00,0x00,0x00,0x00,0x00,0x00,0x00,0x00,0x00,0x00,0x00,0x00,0x00,0x00,0x00,
0x00,0x00,0x00,0x00,0x00,0x00,0x00,0x00,0x00,0x00,0x00,0x00,0x00,0x00,0x00,0x00,
0x00,0x00,0x00,0x00,0x00,0x00,0x00,0x00,0x00,0x00,0x00,0x00,0x00,0x00,0x00,0x00,
0x00,0x00,0x00,0x00,0x00,0x00,0x00,0x00,0x00,0x00,0x00,0x00,0x00,0x00,0x00,0x00,
0x00,0x00,0x00,0x00,0x00,0x00,0x00,0x00,0x00,0x00,0x00,0x00,0x00,0x00,0x00,0x00,
0x00,0x00,0x00,0x00,0x00,0x00,0x00,0x00,0x00,0x00,0x00,0x00,0x00,0x00,0x00,0x00,
0x00,0x00,0x00,0x00,0x00,0x00,0x00,0x00,0x00,0x00,0x00,0x00,0x00,0x00,0x00,0x00,
0x00,0x00,0x00,0x00,0x00,0x00,0x00,0x00,0x00,0x00,0x00,0x00,0x00,0x00,0x00,0x00,
0x00,0x00,0x00,0x00,0x00,0x00,0x00,0x00,0x00,0x00,0x00,0x00,0x00,0x00,0x00,0x00,
0x00,0x00,0x00,0x00,0x00,0x00,0x00,0x00,0x00,0x00,0x00,0x00,0x00,0x00,0x00,0x00,
0x00,0x00,0x00,0x00,0x00,0x00,0x00,0x00,0x00,0x00,0x00,0x00,0x00,0x00,0x00,0x00,
0x00,0x00,0x00,0x00,0x00,0x00,0x00,0x00,0x00,0x00,0x00,0x00,0x00,0x00,0x00,0x00,
0x00,0x00,0x00,0x00,0x00,0x00,0x00,0x00,0x00,0x00,0x00,0x00,0x00,0x00,0x00,0x00,
0x00,0x00,0x00,0x00,0x00,0x00,0x00,0x00,0x00,0x00,0x00,0x00,0x00,0x00,0x00,0x00,
0x00,0x00,0x00,0x00,0x00,0x00,0x00,0x00,0x00,0x00,0x00,0x00,0x00,0x00,0x00,0x00,
0x00,0x00,0x00,0x00,0x00,0x00,0x00,0x00,0x00,0x00,0x00,0x00,0x00,0x00,0x00,0x00,
0x00,0x00,0x00,0x00,0x00,0x00,0x00,0x00,0x00,0x00,0x00,0x00,0x00,0x00,0x00,0x00,
0x00,0x00,0x00,0x00,0x00,0x00,0x00,0x00,0x00,0x00,0x00,0x00,0x00,0x00,0x00,0x00,
0x00,0x00,0x00,0x00,0x00,0x00,0x00,0x00,0x00,0x00,0x00,0x00,0x00,0x00,0x00,0x00,
0x00,0x00,0x00,0x00,0x00,0x00,0x00,0x00,0x00,0x00,0x00,0x00,0x00,0x00,0x00,0x00,
0x00,0x00,0x00,0x00,0x00,0x00,0x00,0x00,0x00,0x00,0x00,0x00,0x00,0x00,0x00,0x00,
0x00,0x00,0x00,0x00,0x00,0x00,0x00,0x00,0x00,0x00,0x00,0x00,0x00,0x00,0x00,0x00,
0x00,0x00,0x00,0x00,0x00,0x00,0x00,0x00,0x00,0x00,0x00,0x00,0x00,0x00,0x00,0x00,
0x00,0x00,0x00,0x00,0x00,0x00,0x00,0x00,0x00,0x00,0x00,0x00,0x00,0x00,0x00,0x00,
0x00,0x00,0x00,0x00,0x00,0x00,0x00,0x00,0x00,0x00,0x00,0x00,0x00,0x00,0x00,0x00,
0x00,0x00,0x00,0x00,0x00,0x00,0x00,0x00,0x00,0x00,0x00,0x00,0x00,0x00,0x00,0x00,
0x00,0x00,0x00,0x00,0x00,0x00,0x00,0x00,0x00,0x00,0x00,0x00,0x00,0x00,0x00,0x00,
0x00,0x00,0x00,0x00,0x00,0x00,0x00,0x00,0x00,0x00,0x00,0x00,0x00,0x00,0x00,0x00,
0x00,0x00,0x00,0x00,0x00,0x00,0x00,0x00,0x00,0x00,0x00,0x00,0x00,0x00,0x00,0x00,
0x00,0x00,0x00,0x00,0x00,0x00,0x00,0x00,0x00,0x00,0x00,0x00,0x00,0x00,0x00,0x00,
0x00,0x00,0x00,0x00,0x00,0x00,0x00,0x00,0x00,0x00,0x00,0x00,0x00,0x00,0x00,0x00,
0x00,0x00,0x00,0x00,0x00,0x00,0x00,0x00,0x00,0x00,0x00,0x00,0x00,0x00,0x00,0x00,
0x00,0x00,0x00,0x00,0x00,0x00,0x00,0x00,0x00,0x00,0x00,0x00,0x00,0x00,0x00,0x00,
0x00,0x00,0x00,0x00,0x00,0x00,0x00,0x00,0x00,0x00,0x00,0x00,0x00,0x00,0x00,0x00,
0x00,0x00,0x00,0x00,0x00,0x00,0x00,0x00,0x00,0x00,0x00,0x00,0x00,0x00,0x00,0x00,
0x00,0x00,0x00,0x00,0x00,0x00,0x00,0x00,0x00,0x00,0x00,0x00,0x00,0x00,0x00,0x00,
0x00,0x00,0x00,0x00,0x00,0x00,0x00,0x00,0x00,0x00,0x00,0x00,0x00,0x00,0x00,0x00,
0x00,0x00,0x00,0x00,0x00,0x00,0x00,0x00,0x00,0x00,0x00,0x00,0x00,0x00,0x00,0x00,
};
uint8_t BMP1[] =
{
/*--  ������һ��ͼ��C:\Users\Administrator\Desktop\22.bmp  --*/
/*--  ���x�߶�=240x160  --*/
0x00,0x00,0x00,0x00,0x00,0x00,0x00,0x00,0x00,0x00,0x00,0x00,0x00,0x00,0x00,0x00,
0x00,0x00,0x00,0x00,0x00,0x00,0x00,0x00,0x00,0x00,0x00,0x00,0x00,0x00,0x00,0x00,
0x00,0x00,0x00,0x00,0x00,0x00,0x00,0x00,0x00,0x00,0x00,0x00,0x00,0x00,0x00,0x00,
0x00,0x00,0x00,0x00,0x00,0x00,0x00,0x00,0x00,0x00,0x00,0x00,0x00,0x00,0x00,0x00,
0x00,0x00,0x00,0x00,0x00,0x00,0x00,0x00,0x00,0x00,0x00,0x00,0x00,0x00,0x00,0x00,
0x00,0x00,0x00,0x00,0x00,0x00,0x00,0x00,0x00,0x00,0x00,0x00,0x00,0x00,0x00,0x00,
0x00,0x00,0x00,0x00,0x00,0x00,0x00,0x00,0x00,0x00,0x00,0x00,0x00,0x00,0x00,0x00,
0x00,0x00,0x00,0x00,0x00,0x00,0x00,0x00,0x00,0x00,0x00,0x00,0x00,0x00,0x00,0x00,
0x00,0x00,0x00,0x00,0x00,0x00,0x00,0x00,0x00,0x00,0x00,0x00,0x00,0x00,0x00,0x00,
0x00,0x00,0x00,0x00,0x00,0x00,0x00,0x00,0x00,0x00,0x00,0x00,0x00,0x00,0x00,0x00,
0x00,0x00,0x00,0x00,0x00,0x00,0x00,0x00,0x00,0x00,0x00,0x00,0x00,0x00,0x00,0x00,
0x00,0x00,0x00,0x00,0x00,0x00,0x00,0x00,0x00,0x00,0x00,0x00,0x00,0x00,0x00,0x00,
0x00,0x00,0x00,0x00,0x00,0x00,0x00,0x00,0x00,0x00,0x00,0x00,0x00,0x00,0x00,0x00,
0x00,0x00,0x00,0x00,0x00,0x00,0x00,0x00,0x00,0x00,0x00,0x00,0x00,0x00,0x00,0x00,
0x00,0x00,0x00,0x00,0x00,0x00,0x00,0x00,0x00,0x00,0x00,0x00,0x00,0x00,0x00,0x00,
0x00,0x00,0x00,0x00,0x00,0x00,0x00,0x00,0x00,0x00,0x00,0x00,0x00,0x00,0x00,0x00,
0x00,0x00,0x00,0x00,0x00,0x00,0x00,0x00,0x00,0x00,0x00,0x00,0x00,0x00,0x00,0x00,
0x00,0x00,0x00,0x00,0x00,0x00,0x00,0x00,0x00,0x00,0x00,0x00,0x00,0x00,0x00,0x00,
0x00,0x00,0x00,0x00,0x00,0x00,0x00,0x00,0x00,0x00,0x00,0x00,0x00,0x00,0x00,0x00,
0x00,0x00,0x00,0x00,0x00,0x00,0x00,0x00,0x00,0x00,0x00,0x00,0x00,0x00,0x00,0x00,
0x00,0x00,0x00,0x00,0x00,0x00,0x00,0x00,0x00,0x00,0x00,0x00,0x00,0x00,0x00,0x00,
0x00,0x00,0x00,0x00,0x00,0x00,0x00,0x00,0x00,0x00,0x00,0x00,0x00,0x00,0x00,0x00,
0x00,0x00,0x00,0x00,0x00,0x00,0x00,0x00,0x00,0x00,0x00,0x00,0x00,0x00,0x00,0x00,
0x00,0x00,0x00,0x00,0x00,0x00,0x00,0x00,0x00,0x00,0x00,0x00,0x00,0x00,0x00,0x00,
0x00,0x00,0x00,0x00,0x00,0x00,0x00,0x00,0x00,0x00,0x00,0x00,0x00,0x00,0x00,0x00,
0x00,0x00,0x00,0x00,0x00,0x00,0x00,0x00,0x00,0x00,0x00,0x00,0x00,0x00,0x00,0x00,
0x00,0x00,0x00,0x00,0x00,0x00,0x00,0x00,0x00,0x00,0x00,0x00,0x00,0x00,0x00,0x00,
0x00,0x00,0x00,0x00,0x00,0x00,0x00,0x00,0x00,0x00,0x00,0x00,0x00,0x00,0x00,0x00,
0x00,0x00,0x00,0x00,0x00,0x00,0x00,0x00,0x00,0x00,0x00,0x00,0x00,0x00,0x00,0x00,
0x00,0x00,0x00,0x00,0x00,0x00,0x00,0x00,0x00,0x00,0x00,0x00,0x00,0x00,0x00,0x00,
0x00,0x00,0x00,0x00,0x00,0x00,0x00,0x00,0x00,0x00,0x00,0x00,0x00,0x00,0x00,0x00,
0x00,0x00,0x00,0x00,0x00,0x00,0x00,0x00,0x00,0x00,0x00,0x00,0x00,0x00,0x00,0x00,
0x00,0x00,0x00,0x00,0x00,0x00,0x00,0x00,0x00,0x00,0x00,0x00,0x00,0x00,0x00,0x00,
0x00,0x00,0x00,0x00,0x00,0x00,0x00,0x00,0x00,0x00,0x00,0x00,0x00,0x00,0x00,0x00,
0x00,0x00,0x00,0x00,0x00,0x00,0x00,0x00,0x00,0x00,0x00,0x00,0x00,0x00,0x00,0x00,
0x00,0x00,0x00,0x00,0x00,0x00,0x00,0x00,0x00,0x00,0x00,0x00,0x00,0x00,0x00,0x00,
0x00,0x00,0x00,0x00,0x00,0x00,0x00,0x00,0x00,0x00,0x00,0x00,0x00,0x00,0x00,0x00,
0x00,0x00,0x00,0x00,0x00,0x00,0x00,0x00,0x00,0x00,0x00,0x00,0x00,0x00,0x00,0x00,
0x00,0x00,0x00,0x00,0x00,0x00,0x00,0x00,0x00,0x00,0x00,0x00,0x00,0x00,0x00,0x00,
0x00,0x00,0x00,0x00,0x00,0x00,0x00,0x00,0x00,0x00,0x00,0x00,0x00,0x00,0x00,0x00,
0x00,0x00,0x00,0x00,0x00,0x00,0x00,0x00,0x00,0x00,0x00,0x00,0x00,0x00,0x00,0x00,
0x00,0x00,0x00,0x00,0x00,0x00,0x00,0x00,0x00,0x00,0x00,0x00,0x00,0x00,0x00,0x00,
0x00,0x00,0x00,0x00,0x00,0x00,0x00,0x00,0x00,0x00,0x00,0x00,0x00,0x00,0x00,0x00,
0x00,0x00,0x00,0x00,0x00,0x00,0x00,0x00,0x00,0x00,0x00,0x00,0x00,0x00,0x00,0x00,
0x00,0x00,0x00,0x00,0x00,0x00,0x00,0x00,0x00,0x00,0x00,0x00,0x00,0x00,0x00,0x00,
0x00,0x00,0x00,0x00,0x00,0x00,0x00,0x00,0x00,0x00,0x00,0x00,0x00,0x00,0x00,0x00,
0x00,0x00,0x00,0x00,0x00,0x00,0x00,0x00,0x00,0x00,0x00,0x00,0x00,0x00,0x00,0x00,
0x00,0x00,0x00,0x00,0x00,0x00,0x00,0x00,0x00,0x00,0x00,0x00,0x00,0x00,0x00,0x00,
0x00,0x00,0x00,0x00,0x00,0x00,0x00,0x00,0x00,0x00,0x00,0x00,0x00,0x00,0x00,0x00,
0x00,0x00,0x00,0x00,0x00,0x00,0x00,0x00,0x00,0x00,0x00,0x00,0x00,0x00,0x00,0x00,
0x00,0x00,0x00,0x00,0x00,0x00,0x00,0x00,0x00,0x00,0x00,0x00,0x00,0x00,0x00,0x00,
0x00,0x00,0x00,0x00,0x00,0x00,0x00,0x00,0x00,0x00,0x00,0x00,0x00,0x00,0x00,0x00,
0x00,0x00,0x00,0x00,0x00,0x00,0x00,0x00,0x00,0x00,0x00,0x00,0x00,0x00,0x00,0x00,
0x00,0x00,0x00,0x00,0x00,0x00,0x00,0x00,0x00,0x00,0x00,0x00,0x00,0x00,0x00,0x00,
0x00,0x00,0x00,0x00,0x00,0x00,0x00,0x00,0x00,0x00,0x00,0x00,0x00,0x00,0x00,0x00,
0x00,0x00,0x00,0x00,0x00,0x00,0x00,0x00,0x00,0x00,0x00,0x00,0x00,0x00,0x00,0x00,
0x00,0x00,0x00,0x00,0x00,0x00,0x00,0x00,0x00,0x00,0x00,0x00,0x00,0x00,0x00,0x00,
0x00,0x00,0x00,0x00,0x00,0x00,0x00,0x00,0x00,0x00,0x00,0x00,0x00,0x00,0x00,0x00,
0x00,0x00,0x00,0x00,0x00,0x00,0x00,0x00,0x00,0x00,0x00,0x00,0x00,0x00,0x00,0x00,
0x00,0x00,0x00,0x00,0x00,0x00,0x00,0x00,0x00,0x00,0x00,0x00,0x00,0x00,0x00,0x00,
0x00,0x00,0x00,0x00,0x00,0x00,0x7F,0x80,0x00,0x00,0x00,0x06,0x00,0x00,0x00,0x00,
0x00,0x00,0x00,0x00,0x00,0x03,0x00,0x00,0x00,0x00,0x00,0x00,0x00,0x00,0x00,0x00,
0x00,0x00,0x00,0x00,0x7F,0x80,0x00,0x00,0x00,0x7F,0x00,0x00,0x02,0x00,0x00,0x00,
0x00,0x00,0x00,0x7F,0x80,0x00,0x00,0x00,0x00,0x00,0x00,0x00,0x00,0x00,0x00,0x00,
0x00,0x00,0x7F,0x80,0x00,0x00,0x00,0xFF,0x00,0x00,0x07,0x07,0xFF,0xFF,0xFE,0x00,
0x00,0xFF,0x80,0x00,0x00,0x00,0x00,0x00,0x00,0x00,0x00,0x00,0x00,0x00,0x00,0x00,
0x7F,0x80,0x00,0x00,0x00,0x7F,0x80,0x00,0x0F,0xC7,0xFF,0xFF,0xFE,0x00,0x00,0x7F,
0x80,0x00,0x00,0x00,0x00,0x00,0x00,0x00,0x00,0x00,0x00,0x00,0x00,0x00,0x7F,0x80,
0x00,0x00,0x00,0x7F,0x80,0x00,0x1F,0xE7,0xFF,0xFF,0xFE,0x1F,0xFF,0xFF,0xFF,0xFE,
0x00,0x00,0x00,0x00,0x00,0x00,0x00,0x00,0x00,0x00,0x00,0x00,0x7F,0x80,0x00,0x00,
0x00,0x7F,0x80,0x00,0x1F,0xF7,0xFF,0xFF,0xFE,0x3F,0xFF,0xFF,0xFF,0xFF,0x00,0x00,
0x00,0x00,0x00,0x00,0x00,0x00,0x00,0x00,0x00,0x00,0x7F,0x80,0x00,0x3F,0xFF,0xFF,
0xFF,0xFF,0x0F,0xFF,0xFF,0xFF,0xFE,0x3F,0xFF,0xFF,0xFF,0xFF,0x00,0x00,0x00,0x00,
0x00,0x00,0x00,0x00,0x00,0x00,0x1F,0xFF,0xFF,0xFF,0xFE,0x7F,0xFF,0xFF,0xFF,0xFF,
0x87,0xFF,0xFF,0xFF,0xFE,0x3F,0xFF,0xFF,0xFF,0xFF,0x00,0x00,0x00,0x00,0x00,0x00,
0x00,0x00,0x00,0x00,0x1F,0xFF,0xFF,0xFF,0xFE,0x7F,0xFF,0xFF,0xFF,0xFF,0x83,0xF8,
0x78,0x01,0xFE,0x3F,0xFF,0xFF,0xFF,0xFF,0x00,0x00,0x00,0x00,0x00,0x00,0x00,0x00,
0x00,0x00,0x1F,0xFF,0xFF,0xFF,0xFE,0x7F,0xFF,0xFF,0xFF,0xFF,0x81,0xF1,0xF8,0x01,
0xFC,0x3F,0xFF,0xFF,0xFF,0xFF,0x00,0x00,0x00,0x00,0x00,0x00,0x00,0x00,0x00,0x00,
0x1F,0xFF,0xFF,0xFF,0xFE,0x7F,0xFF,0xFF,0xFF,0xFF,0x80,0xE3,0xF8,0x01,0xFC,0x3F,
0x80,0x00,0x00,0x7F,0x00,0x00,0x00,0x00,0x00,0x00,0x00,0x00,0x00,0x00,0x1F,0xFF,
0xFF,0xFF,0xFE,0x7F,0xFF,0xFF,0xFF,0xFF,0x8C,0x03,0xF8,0x01,0xFC,0x3F,0x80,0x00,
0x00,0x7F,0x00,0x00,0x00,0x00,0x00,0x00,0x00,0x00,0x00,0x00,0x1F,0xFF,0xFF,0xFF,
0xFE,0x00,0xFE,0x00,0x1F,0xE0,0x1E,0x03,0xFC,0x03,0xFC,0x3F,0x80,0x00,0x00,0x7F,
0x00,0x00,0x00,0x00,0x00,0x00,0x00,0x00,0x00,0x00,0x1F,0xC0,0x7F,0x80,0xFE,0x00,
0xFF,0x00,0x3F,0xC0,0x3F,0x81,0xFC,0x03,0xFC,0x3F,0xFF,0xFF,0xFF,0xFF,0x00,0x00,
0x00,0x00,0x00,0x00,0x00,0x00,0x00,0x00,0x1F,0xC0,0x7F,0x80,0xFE,0x00,0xFF,0x00,
0x3F,0xC0,0x7F,0xC1,0xFC,0x03,0xF8,0x3F,0xFF,0xFF,0xFF,0xFF,0x00,0x00,0x00,0x00,
0x00,0x00,0x00,0x00,0x00,0x00,0x1F,0xC0,0x7F,0x80,0xFE,0x00,0x7F,0x00,0x7F,0x80,
0x7F,0xE1,0xFE,0x07,0xF8,0x00,0x7F,0xFF,0xFF,0x80,0x00,0x00,0x00,0x00,0x00,0x00,
0x00,0x00,0x00,0x00,0x1F,0xC0,0x7F,0x80,0xFE,0x00,0x7F,0x80,0x7F,0x80,0x3F,0xF0,
0xFE,0x07,0xF8,0x00,0x7F,0xFF,0xFF,0x80,0x00,0x00,0x00,0x00,0x00,0x00,0x00,0x00,
0x00,0x00,0x1F,0xC0,0x7F,0x80,0xFE,0x00,0x3F,0x80,0xFF,0x80,0x1F,0xF8,0xFF,0x0F,
0xF0,0x00,0x7F,0xFF,0xFF,0x80,0x00,0x00,0x00,0x00,0x00,0x00,0x00,0x00,0x00,0x00,
0x1F,0xC0,0x7F,0x80,0xFE,0x00,0x3F,0xC0,0xFF,0x00,0x07,0xF0,0xFF,0x0F,0xF0,0x00,
0x00,0x01,0xFF,0x00,0x00,0x00,0x00,0x00,0x00,0x00,0x00,0x00,0x00,0x00,0x1F,0xC0,
0x7F,0x80,0xFE,0x00,0x3F,0xE1,0xFF,0x00,0x03,0xE0,0x7F,0x9F,0xE0,0x00,0x00,0x07,
0xFE,0x00,0x00,0x00,0x00,0x00,0x00,0x00,0x00,0x00,0x00,0x00,0x1F,0xC0,0x7F,0x80,
0xFE,0x00,0x1F,0xE3,0xFE,0x00,0x01,0xC0,0x7F,0x9F,0xE0,0x00,0x00,0x1F,0xF8,0x00,
0x00,0x00,0x00,0x00,0x00,0x00,0x00,0x00,0x00,0x00,0x1F,0xFF,0xFF,0xFF,0xFE,0x00,
0x0F,0xF3,0xFC,0x00,0x00,0xC0,0x3F,0xFF,0xE0,0x00,0x00,0x3F,0xF0,0x00,0x00,0x00,
0x00,0x00,0x00,0x00,0x00,0x00,0x00,0x00,0x1F,0xFF,0xFF,0xFF,0xFE,0x00,0x0F,0xFF,
0xFC,0x00,0x03,0x00,0x3F,0xFF,0xC0,0x00,0x00,0x3F,0xC0,0x00,0x00,0x00,0x00,0x00,
0x00,0x00,0x00,0x00,0x00,0x00,0x1F,0xFF,0xFF,0xFF,0xFE,0x00,0x07,0xFF,0xF8,0x00,
0x03,0xE0,0x1F,0xFF,0x80,0x7F,0xFF,0xFF,0xFF,0xFF,0x80,0x00,0x00,0x00,0x00,0x00,
0x00,0x00,0x00,0x00,0x1F,0xFF,0xFF,0xFF,0xFE,0x00,0x03,0xFF,0xF0,0x00,0x03,0xF8,
0x1F,0xFF,0x80,0x7F,0xFF,0xFF,0xFF,0xFF,0x80,0x00,0x00,0x00,0x00,0x00,0x00,0x00,
0x00,0x00,0x1F,0xFF,0xFF,0xFF,0xFE,0x00,0x03,0xFF,0xF0,0x00,0x07,0xF0,0x0F,0xFF,
0x00,0x7F,0xFF,0xFF,0xFF,0xFF,0x80,0x00,0x00,0x00,0x00,0x00,0x00,0x00,0x00,0x00,
0x1F,0xFF,0xFF,0xFF,0xFE,0x00,0x01,0xFF,0xE0,0x00,0x07,0xF0,0x07,0xFF,0x00,0x7F,
0xFF,0xFF,0xFF,0xFF,0x80,0x00,0x00,0x00,0x00,0x00,0x00,0x00,0x00,0x00,0x1F,0xC0,
0x7F,0x80,0xFE,0x00,0x03,0xFF,0xE0,0x00,0x07,0xF0,0x0F,0xFE,0x00,0x7F,0xFF,0xFF,
0xFF,0xFF,0x80,0x00,0x00,0x00,0x00,0x00,0x00,0x00,0x00,0x00,0x1F,0xC0,0x7F,0x80,
0xFE,0x00,0x07,0xFF,0xF8,0x00,0x0F,0xE0,0x1F,0xFF,0x80,0x3F,0xFF,0xFF,0xFF,0xFF,
0x00,0x00,0x00,0x00,0x00,0x00,0x00,0x00,0x00,0x00,0x1F,0xC0,0x7F,0x80,0xFE,0x00,
0x1F,0xFF,0xFE,0x00,0x0F,0xE0,0x3F,0xFF,0xC0,0x00,0x00,0x3F,0xC0,0x00,0x00,0x00,
0x00,0x00,0x00,0x00,0x00,0x00,0x00,0x00,0x00,0x00,0x7F,0x80,0x00,0x00,0x7F,0xFF,
0xFF,0x80,0x0F,0xE0,0xFF,0xFF,0xF0,0x00,0x00,0x3F,0xC0,0x00,0x00,0x00,0x00,0x00,
0x00,0x00,0x00,0x00,0x00,0x00,0x00,0x00,0x7F,0x80,0x00,0x01,0xFF,0xFF,0xFF,0xF0,
0x1F,0xC1,0xFF,0xFF,0xFC,0x00,0x00,0x3F,0xC0,0x00,0x00,0x00,0x00,0x00,0x00,0x00,
0x00,0x00,0x00,0x00,0x00,0x00,0x7F,0x80,0x00,0x0F,0xFF,0xF3,0xFF,0xFE,0x1F,0xC7,
0xFF,0xFF,0xFF,0x00,0x00,0x3F,0xC0,0x00,0x00,0x00,0x00,0x00,0x00,0x00,0x00,0x00,
0x00,0x00,0x00,0x00,0x7F,0x80,0x00,0x7F,0xFF,0xE1,0xFF,0xFF,0x9F,0xDF,0xFF,0x9F,
0xFF,0x80,0x3F,0xFF,0xC0,0x00,0x00,0x00,0x00,0x00,0x00,0x00,0x00,0x00,0x00,0x00,
0x00,0x00,0x7F,0x80,0x00,0x7F,0xFF,0x80,0x7F,0xFF,0x3F,0xBF,0xFE,0x0F,0xFF,0x00,
0x3F,0xFF,0xC0,0x00,0x00,0x00,0x00,0x00,0x00,0x00,0x00,0x00,0x00,0x00,0x00,0x00,
0x7F,0x80,0x00,0x3F,0xFE,0x00,0x3F,0xFE,0x3F,0x9F,0xFC,0x03,0xFF,0x00,0x1F,0xFF,
0x80,0x00,0x00,0x00,0x00,0x00,0x00,0x00,0x00,0x00,0x00,0x00,0x00,0x00,0x7F,0x80,
0x00,0x1F,0xF8,0x00,0x0F,0xFE,0x7F,0x9F,0xF0,0x01,0xFE,0x00,0x1F,0xFF,0x80,0x00,
0x00,0x00,0x00,0x00,0x00,0x00,0x00,0x00,0x00,0x00,0x00,0x00,0x7F,0x80,0x00,0x0F,
0xE0,0x00,0x01,0xFC,0x7F,0x0F,0xE0,0x00,0x7C,0x00,0x1F,0xFF,0x00,0x00,0x00,0x00,
0x00,0x00,0x00,0x00,0x00,0x00,0x00,0x00,0x00,0x00,0x7F,0x80,0x00,0x0F,0x80,0x00,
0x00,0x78,0x0F,0x07,0x80,0x00,0x1C,0x00,0x1F,0xFE,0x00,0x00,0x00,0x00,0x00,0x00,
0x00,0x00,0x00,0x00,0x00,0x00,0x00,0x00,0x7F,0x80,0x00,0x04,0x00,0x00,0x00,0x00,
0x00,0x02,0x00,0x00,0x00,0x00,0x00,0x00,0x00,0x00,0x00,0x00,0x00,0x00,0x00,0x00,
0x00,0x00,0x00,0x00,0x00,0x00,0x00,0x00,0x00,0x00,0x00,0x00,0x00,0x00,0x00,0x00,
0x00,0x00,0x00,0x00,0x00,0x00,0x00,0x00,0x00,0x00,0x00,0x00,0x00,0x00,0x00,0x00,
0x00,0x00,0x00,0x00,0x00,0x00,0x00,0x00,0x00,0x00,0x00,0x00,0x00,0x00,0x00,0x00,
0x00,0x00,0x00,0x00,0x00,0x00,0x00,0x00,0x00,0x00,0x00,0x00,0x00,0x00,0x00,0x00,
0x00,0x00,0x00,0x00,0x00,0x00,0x00,0x00,0x00,0x00,0x00,0x00,0x00,0x00,0x00,0x00,
0x00,0x00,0x00,0x00,0x00,0x00,0x00,0x00,0x00,0x00,0x00,0x00,0x00,0x00,0x00,0x00,
0x00,0x00,0x00,0x00,0x00,0x00,0x00,0x00,0x00,0x00,0x00,0x00,0x00,0x00,0x00,0x00,
0x00,0x00,0x00,0x00,0x00,0x00,0x00,0x00,0x00,0x00,0x00,0x00,0x00,0x00,0x00,0x00,
0x00,0x00,0x00,0x00,0x00,0x00,0x00,0x00,0x00,0x00,0x00,0x00,0x00,0x00,0x00,0x00,
0x00,0x00,0x00,0x00,0x00,0x00,0x00,0x00,0x00,0x00,0x00,0x00,0x00,0x00,0x00,0x00,
0x00,0x00,0x00,0x00,0x00,0x00,0x00,0x00,0x00,0x00,0x00,0x00,0x00,0x00,0x00,0x00,
0x00,0x00,0x00,0x00,0x00,0x00,0x00,0x00,0x00,0x00,0x00,0x00,0x00,0x00,0x00,0x00,
0x00,0x00,0x00,0x00,0x00,0x00,0x00,0x00,0x00,0x00,0x00,0x00,0x00,0x00,0x00,0x00,
0x00,0x00,0x00,0x00,0x00,0x00,0x00,0x00,0x00,0x00,0x00,0x00,0x00,0x00,0x00,0x00,
0x00,0x00,0x00,0x00,0x00,0x00,0x00,0x00,0x00,0x00,0x00,0x00,0x00,0x00,0x00,0x00,
0x00,0x00,0x00,0x00,0x00,0x00,0x00,0x00,0x00,0x00,0x00,0x00,0x00,0x00,0x00,0x00,
0x00,0x00,0x00,0x00,0x00,0x00,0x00,0x00,0x00,0x00,0x00,0x00,0x00,0x00,0x00,0x00,
0x00,0x00,0x00,0x00,0x00,0x00,0x00,0x00,0x00,0x00,0x00,0x00,0x00,0x00,0x00,0x00,
0x00,0x00,0x00,0x00,0x00,0x00,0x00,0x00,0x00,0x00,0x00,0x00,0x00,0x00,0x00,0x00,
0x00,0x00,0x00,0x00,0x00,0x00,0x00,0x00,0x00,0x00,0x00,0x00,0x00,0x00,0x00,0x00,
0x00,0x00,0x00,0x00,0x00,0x00,0x00,0x00,0x00,0x00,0x00,0x00,0x00,0x00,0x00,0x00,
0x00,0x00,0x00,0x00,0x00,0x00,0x00,0x00,0x00,0x00,0x00,0x00,0x00,0x00,0x00,0x00,
0x00,0x00,0x00,0x00,0x00,0x00,0x00,0x00,0x00,0x00,0x00,0x00,0x00,0x00,0x00,0x00,
0x00,0x00,0x00,0x00,0x00,0x00,0x00,0x00,0x00,0x00,0x00,0x00,0x00,0x00,0x00,0x00,
0x00,0x00,0x00,0x00,0x00,0x00,0x00,0x00,0x00,0x00,0x00,0x00,0x00,0x00,0x00,0x00,
0x00,0x00,0x00,0x00,0x00,0x00,0x00,0x00,0x00,0x00,0x00,0x00,0x00,0x00,0x00,0x00,
0x00,0x00,0x00,0x00,0x00,0x00,0x00,0x00,0x00,0x00,0x00,0x00,0x00,0x00,0x00,0x00,
0x00,0x00,0x00,0x00,0x00,0x00,0x00,0x00,0x00,0x00,0x00,0x00,0x00,0x00,0x00,0x00,
0x00,0x00,0x00,0x00,0x00,0x00,0x00,0x00,0x00,0x00,0x00,0x00,0x00,0x00,0x00,0x00,
0x00,0x00,0x00,0x00,0x00,0x00,0x00,0x00,0x00,0x00,0x00,0x00,0x00,0x00,0x00,0x00,
0x00,0x00,0x00,0x00,0x00,0x00,0x00,0x00,0x00,0x00,0x00,0x00,0x00,0x00,0x00,0x00,
0x00,0x00,0x00,0x00,0x00,0x00,0x00,0x00,0x00,0x00,0x00,0x00,0x00,0x00,0x00,0x00,
0x00,0x00,0x00,0x00,0x00,0x00,0x00,0x00,0x00,0x00,0x00,0x00,0x00,0x00,0x00,0x00,
0x00,0x00,0x00,0x00,0x00,0x00,0x00,0x00,0x00,0x00,0x00,0x00,0x00,0x00,0x00,0x00,
0x00,0x00,0x00,0x00,0x00,0x00,0x00,0x00,0x00,0x00,0x00,0x00,0x00,0x00,0x00,0x00,
0x00,0x00,0x00,0x00,0x00,0x00,0x00,0x00,0x00,0x00,0x00,0x00,0x00,0x00,0x00,0x00,
0x00,0x00,0x00,0x00,0x00,0x00,0x00,0x00,0x00,0x00,0x00,0x00,0x00,0x00,0x00,0x00,
0x00,0x00,0x00,0x00,0x00,0x00,0x00,0x00,0x00,0x00,0x00,0x00,0x00,0x00,0x00,0x00,
0x00,0x00,0x00,0x00,0x00,0x00,0x00,0x00,0x00,0x00,0x00,0x00,0x00,0x00,0x00,0x00,
0x00,0x00,0x00,0x00,0x00,0x00,0x00,0x00,0x00,0x00,0x00,0x00,0x00,0x00,0x00,0x00,
0x00,0x00,0x00,0x00,0x00,0x00,0x00,0x00,0x00,0x00,0x00,0x00,0x00,0x00,0x00,0x00,
0x00,0x00,0x00,0x00,0x00,0x00,0x00,0x00,0x00,0x00,0x00,0x00,0x00,0x00,0x00,0x00,
0x7E,0x00,0x00,0x00,0x00,0x00,0x00,0x00,0x00,0x03,0x00,0x00,0x00,0x00,0x00,0x00,
0x00,0x00,0x00,0x00,0x00,0x00,0x1C,0x00,0x00,0x00,0x7E,0x0E,0x00,0x00,0x7E,0x60,
0x00,0x06,0x00,0x00,0x00,0x00,0x00,0x3F,0x80,0x00,0x00,0x00,0x00,0x00,0x00,0x00,
0x00,0x00,0x00,0x00,0x1F,0x3F,0xFF,0xC0,0x7E,0x3F,0x00,0x00,0x7F,0xF0,0x03,0xFE,
0xFF,0xFF,0xFC,0x00,0x00,0x7F,0x80,0x00,0x00,0x00,0x00,0x00,0x00,0x00,0x00,0x00,
0x00,0x00,0x3F,0xBF,0xFF,0xC0,0x7E,0x7F,0x00,0x00,0x7F,0xF8,0xFF,0xFF,0xFF,0xFF,
0xFC,0x00,0x00,0x7F,0xC0,0x00,0x00,0x00,0x00,0x00,0x00,0x00,0x00,0x00,0x00,0x00,
0x7F,0xFF,0xFF,0xDF,0x7E,0x7F,0x80,0x00,0x7F,0xFC,0xFF,0xFF,0xFF,0xFF,0xFC,0x1F,
0xFF,0xFF,0xFF,0xFF,0x00,0x00,0x00,0x00,0x00,0x00,0x00,0x00,0x00,0x00,0x3F,0xFF,
0xFF,0xDF,0x7E,0x3F,0xC0,0x00,0x7E,0xFE,0xFF,0xFF,0xFF,0xFF,0xFC,0x1F,0xFF,0xFF,
0xFF,0xFF,0x00,0x00,0x00,0x00,0x00,0x00,0x00,0x00,0x00,0x00,0x1F,0xFF,0xFF,0xDF,
0x7E,0x1F,0xC0,0x00,0x7E,0xFE,0xFF,0xFF,0xFF,0xFF,0xFC,0x1F,0xFF,0xFF,0xFF,0xFF,
0x00,0x00,0x00,0x00,0x00,0x00,0x00,0x00,0x00,0x00,0x0F,0xFE,0x07,0xDF,0x7E,0x1F,
0xE0,0x00,0x7E,0x78,0x7F,0xF8,0xFE,0x01,0xFC,0x1F,0xFF,0xFF,0xFF,0xFF,0x00,0x00,
0x00,0x00,0x00,0x00,0x00,0x00,0x00,0x00,0x07,0xBE,0x07,0xDF,0x7E,0x0F,0xFF,0xFF,
0xFF,0xFF,0x77,0xF0,0xFE,0x01,0xFC,0x1F,0xFF,0xFF,0xFF,0xFF,0x00,0x00,0x00,0x00,
0x00,0x00,0x00,0x00,0x00,0x00,0x03,0x3E,0xFF,0xDF,0x7E,0x07,0xFF,0xFF,0xFF,0xFF,
0x07,0xF0,0xFE,0x01,0xFC,0x1F,0xFF,0xFF,0xFF,0xFE,0x00,0x00,0x00,0x00,0x00,0x00,
0x00,0x00,0x00,0x00,0x00,0x3E,0xFF,0xDF,0x7E,0x07,0x3F,0xFF,0xFF,0xFF,0x07,0xF0,
0xFE,0x01,0xFC,0x1F,0xC0,0x00,0x00,0x00,0x00,0x00,0x00,0x00,0x00,0x00,0x00,0x00,
0x00,0x00,0x18,0x3E,0xFF,0xDF,0x7E,0x00,0x3F,0xFF,0xFF,0xFF,0x07,0xF0,0xFF,0xFF,
0xFC,0x1F,0xDF,0xFF,0xFF,0xF8,0x00,0x00,0x00,0x00,0x00,0x00,0x00,0x00,0x00,0x00,
0x3C,0x3E,0xFF,0xDF,0x7E,0x00,0x3F,0xFF,0xFF,0xFF,0xFF,0xFF,0xFF,0xFF,0xFC,0x1F,
0xDF,0xFF,0xFF,0xFC,0x00,0x00,0x00,0x00,0x00,0x00,0x00,0x00,0x00,0x00,0x7E,0x3E,
0xFF,0xDF,0x7E,0xFF,0xDF,0xFF,0xFF,0xFF,0xFF,0xFF,0xFF,0xFF,0xFC,0x1F,0xDF,0xFF,
0xFF,0xFC,0x00,0x00,0x00,0x00,0x00,0x00,0x00,0x00,0x00,0x00,0xFF,0xBE,0xFF,0xDF,
0x7E,0xFF,0xC0,0x00,0x7F,0x00,0xFF,0xFF,0xFF,0xFF,0xFC,0x1F,0xDF,0xFF,0xFF,0xFC,
0x00,0x00,0x00,0x00,0x00,0x00,0x00,0x00,0x00,0x00,0xFF,0xFE,0xFF,0xDF,0x7E,0xFF,
0xC0,0x00,0x7F,0x00,0xFF,0xFF,0xFF,0xFF,0xFC,0x1F,0xDF,0xFF,0xFF,0xFC,0x00,0x00,
0x00,0x00,0x00,0x00,0x00,0x00,0x00,0x00,0x7F,0xFE,0xFF,0xDF,0x7E,0xFF,0xC0,0x00,
0x7F,0x00,0xFF,0xFF,0x00,0x00,0x00,0x1F,0xDF,0xFF,0xFF,0xF8,0x00,0x00,0x00,0x00,
0x00,0x00,0x00,0x00,0x00,0x00,0x3F,0xFE,0xFF,0xDF,0x7E,0xFF,0xDF,0xFF,0xFF,0x00,
0x0F,0xF0,0x00,0x00,0x00,0x1F,0xC1,0xF8,0x1F,0xF0,0x00,0x00,0x00,0x00,0x00,0x00,
0x00,0x00,0x00,0x00,0x1F,0xBE,0xFF,0xDF,0x7E,0x7F,0xDF,0xFF,0xFF,0x00,0x0F,0xF1,
0xFF,0xFF,0xFE,0x1F,0xC3,0xFE,0x7F,0xE0,0x00,0x00,0x00,0x00,0x00,0x00,0x00,0x00,
0x00,0x00,0x07,0x3E,0xFF,0xDF,0x7E,0x1F,0xDF,0xFF,0xFF,0x00,0x1F,0xF1,0xFF,0xFF,
0xFE,0x1F,0xC3,0xFF,0xFF,0x80,0x00,0x00,0x00,0x00,0x00,0x00,0x00,0x00,0x00,0x00,
0x02,0x3E,0xFF,0xDF,0x7E,0x1F,0xDF,0xFF,0xFF,0x00,0x1F,0xF9,0xFF,0xFF,0xFE,0x1F,
0xC0,0xFF,0xFF,0x00,0x00,0x00,0x00,0x00,0x00,0x00,0x00,0x00,0x00,0x00,0x00,0x3E,
0xFF,0xDF,0x7E,0x1F,0xDF,0xFF,0xFF,0x00,0x1F,0xFF,0xFF,0xFF,0xFE,0x1F,0xC0,0x7F,
0xFC,0x00,0x00,0x00,0x00,0x00,0x00,0x00,0x00,0x00,0x00,0x00,0x0C,0x3F,0xFF,0xDF,
0x7E,0x1F,0xDF,0xFF,0xFF,0x00,0x3F,0xFF,0xFF,0xFF,0xFE,0x1F,0xFF,0xFF,0xFF,0xFF,
0x00,0x00,0x00,0x00,0x00,0x00,0x00,0x00,0x00,0x00,0x0F,0xBF,0xFF,0xDF,0x7E,0x1F,
0xC1,0xFC,0x3F,0x00,0x7F,0xFF,0x80,0xFC,0x00,0x1F,0xFF,0xFF,0xFF,0xFF,0x00,0x00,
0x00,0x00,0x00,0x00,0x00,0x00,0x00,0x00,0x0F,0xFF,0xF7,0xDF,0x7E,0x1F,0xC1,0xFC,
0x3F,0x00,0x7F,0xFF,0xC0,0xFC,0x00,0x1F,0xFF,0xFF,0xFF,0xFF,0x00,0x00,0x00,0x00,
0x00,0x00,0x00,0x00,0x00,0x00,0x0F,0xFF,0xF7,0xDF,0x7E,0x1F,0xC1,0xFC,0x3F,0x80,
0xFF,0xFF,0x80,0xFC,0x00,0x1F,0xFF,0xFF,0xFF,0xFF,0x00,0x00,0x00,0x00,0x00,0x00,
0x00,0x00,0x00,0x00,0x1F,0xFF,0xF7,0xDF,0x7E,0x1F,0xC1,0xFC,0x3F,0x80,0xFF,0xFF,
0xFF,0xFF,0xFC,0x1F,0xFF,0xFF,0xFF,0xFF,0x00,0x00,0x00,0x00,0x00,0x00,0x00,0x00,
0x00,0x00,0x1F,0xDF,0xF0,0x1F,0x7E,0x1F,0xDD,0xFC,0x3F,0xBC,0xFF,0xFE,0xFF,0xFF,
0xFC,0x3F,0xBF,0xFF,0xFF,0xFE,0x00,0x00,0x00,0x00,0x00,0x00,0x00,0x00,0x00,0x00,
0x1F,0xC3,0xFC,0x1F,0x7E,0x1F,0xFD,0xFC,0x3F,0xBF,0x7F,0xF0,0xFF,0xFF,0xFC,0x3F,
0x80,0x07,0xF0,0xFE,0x00,0x00,0x00,0x00,0x00,0x00,0x00,0x00,0x00,0x00,0x1F,0x87,
0xFE,0x1F,0x7E,0x1F,0xFD,0xFC,0x3F,0xBF,0x7F,0xF0,0xFF,0xFF,0xFC,0x3F,0x80,0x07,
0xF0,0xFC,0x00,0x00,0x00,0x00,0x00,0x00,0x00,0x00,0x00,0x00,0x3F,0x87,0xFF,0x1F,
0x7E,0x1F,0xFD,0xFF,0xFF,0xBF,0x77,0xF0,0xFF,0xFF,0xFC,0x3F,0x80,0x07,0xF1,0xFC,
0x00,0x00,0x00,0x00,0x00,0x00,0x00,0x00,0x00,0x00,0x3F,0x8F,0xFF,0x80,0x7E,0x1F,
0xFF,0xFF,0xDF,0xFF,0x77,0xF0,0x00,0xFC,0x00,0x3F,0x80,0x07,0xF1,0xF8,0x00,0x00,
0x00,0x00,0x00,0x00,0x00,0x00,0x00,0x00,0x3F,0x9F,0xDF,0xC0,0xFE,0x1F,0xFF,0xFF,
0xDF,0xFF,0x27,0xF0,0x00,0xFC,0x00,0x7F,0x00,0x07,0xF1,0xF8,0x00,0x00,0x00,0x00,
0x00,0x00,0x00,0x00,0x00,0x00,0x3F,0x3F,0xDF,0xFF,0xFE,0x1F,0xFF,0xFF,0xDF,0xFF,
0x07,0xF7,0xFF,0xFF,0xFF,0x7F,0x00,0x0F,0xF0,0x10,0x00,0x00,0x00,0x00,0x00,0x00,
0x00,0x00,0x00,0x00,0x7F,0xFF,0x8F,0xFF,0xFE,0x1F,0xFF,0xFF,0xDF,0xFE,0x07,0xF7,
0xFF,0xFF,0xFF,0xFF,0x07,0xFF,0xF0,0x00,0x00,0x00,0x00,0x00,0x00,0x00,0x00,0x00,
0x00,0x00,0x7F,0xFF,0x07,0xFF,0xFC,0x3F,0xFF,0xFF,0xCF,0xFE,0x07,0xF7,0xFF,0xFF,
0xFF,0xFF,0x07,0xFF,0xF0,0x00,0x00,0x00,0x00,0x00,0x00,0x00,0x00,0x00,0x00,0x00,
0x7F,0x7E,0x03,0xCF,0xFC,0x1F,0x9F,0xF8,0x0F,0xFE,0x07,0xF7,0xFF,0xFF,0xFF,0x7E,
0x03,0xFF,0xE0,0x00,0x00,0x00,0x00,0x00,0x00,0x00,0x00,0x00,0x00,0x00,0x7E,0x3C,
0x03,0x8F,0xF8,0x0F,0x1E,0x00,0x07,0xFC,0x07,0xF7,0xFF,0xFF,0xFF,0x3E,0x03,0xFF,
0xC0,0x00,0x00,0x00,0x00,0x00,0x00,0x00,0x00,0x00,0x00,0x00,0x1E,0x1C,0x00,0x0F,
0xF0,0x06,0x00,0x00,0x03,0xF8,0x07,0xF3,0xFF,0xFF,0xFE,0x1C,0x03,0xFF,0x80,0x00,
0x00,0x00,0x00,0x00,0x00,0x00,0x00,0x00,0x00,0x00,0x00,0x00,0x00,0x00,0x00,0x00,
0x00,0x00,0x00,0xE0,0x07,0xF0,0x00,0x00,0x00,0x0C,0x00,0x00,0x00,0x00,0x00,0x00,
0x00,0x00,0x00,0x00,0x00,0x00,0x00,0x00,0x00,0x00,0x00,0x00,0x00,0x00,0x00,0x00,
0x00,0x00,0x00,0x00,0x00,0x00,0x00,0x00,0x00,0x00,0x00,0x00,0x00,0x00,0x00,0x00,
0x00,0x00,0x00,0x00,0x00,0x00,0x00,0x00,0x00,0x00,0x00,0x00,0x00,0x00,0x00,0x00,
0x00,0x00,0x00,0x00,0x00,0x00,0x00,0x00,0x00,0x00,0x00,0x00,0x00,0x00,0x00,0x00,
0x00,0x00,0x00,0x00,0x00,0x00,0x00,0x00,0x00,0x00,0x00,0x00,0x00,0x00,0x00,0x00,
0x00,0x00,0x00,0x00,0x00,0x00,0x00,0x00,0x00,0x00,0x00,0x00,0x00,0x00,0x00,0x00,
0x00,0x00,0x00,0x00,0x00,0x00,0x00,0x00,0x00,0x00,0x00,0x00,0x00,0x00,0x00,0x00,
0x00,0x00,0x00,0x00,0x00,0x00,0x00,0x00,0x00,0x00,0x00,0x00,0x00,0x00,0x00,0x00,
0x00,0x00,0x00,0x00,0x00,0x00,0x00,0x00,0x00,0x00,0x00,0x00,0x00,0x00,0x00,0x00,
0x00,0x00,0x00,0x00,0x00,0x00,0x00,0x00,0x00,0x00,0x00,0x00,0x00,0x00,0x00,0x00,
0x00,0x00,0x00,0x00,0x00,0x00,0x00,0x00,0x00,0x00,0x00,0x00,0x00,0x00,0x00,0x00,
0x00,0x00,0x00,0x00,0x00,0x00,0x00,0x00,0x00,0x00,0x00,0x00,0x00,0x00,0x00,0x00,
0x00,0x00,0x00,0x00,0x00,0x00,0x00,0x00,0x00,0x00,0x00,0x00,0x00,0x00,0x00,0x00,
0x00,0x00,0x00,0x00,0x00,0x00,0x00,0x00,0x00,0x00,0x00,0x00,0x00,0x00,0x00,0x00,
0x00,0x00,0x00,0x00,0x00,0x00,0x00,0x00,0x00,0x00,0x00,0x00,0x00,0x00,0x00,0x00,
0x00,0x00,0x00,0x00,0x00,0x00,0x00,0x00,0x00,0x00,0x00,0x00,0x00,0x00,0x00,0x00,
0x00,0x00,0x00,0x00,0x00,0x00,0x00,0x00,0x00,0x00,0x00,0x00,0x00,0x00,0x00,0x00,
0x00,0x00,0x00,0x00,0x00,0x00,0x00,0x00,0x00,0x00,0x00,0x00,0x00,0x00,0x00,0x00,
0x00,0x00,0x00,0x00,0x00,0x00,0x00,0x00,0x00,0x00,0x00,0x00,0x00,0x00,0x00,0x00,
0x00,0x00,0x00,0x00,0x00,0x00,0x00,0x00,0x00,0x00,0x00,0x00,0x00,0x00,0x00,0x00,
0x00,0x00,0x00,0x00,0x00,0x00,0x00,0x00,0x00,0x00,0x00,0x00,0x00,0x00,0x00,0x00,
0x00,0x00,0x00,0x00,0x00,0x00,0x00,0x00,0x00,0x00,0x00,0x00,0x00,0x00,0x00,0x00,
0x00,0x00,0x00,0x00,0x00,0x00,0x00,0x00,0x00,0x00,0x00,0x00,0x00,0x00,0x00,0x00,
0x00,0x00,0x00,0x00,0x00,0x00,0x00,0x00,0x00,0x00,0x00,0x00,0x00,0x00,0x00,0x00,
0x00,0x00,0x00,0x00,0x00,0x00,0x00,0x00,0x00,0x00,0x00,0x00,0x00,0x00,0x00,0x00,
0x00,0x00,0x00,0x00,0x00,0x00,0x00,0x00,0x00,0x00,0x00,0x00,0x00,0x00,0x00,0x00,
0x00,0x00,0x00,0x00,0x00,0x00,0x00,0x00,0x00,0x00,0x00,0x00,0x00,0x00,0x00,0x00,
0x00,0x00,0x00,0x00,0x00,0x00,0x00,0x00,0x00,0x00,0x00,0x00,0x00,0x00,0x00,0x00,
0x00,0x00,0x00,0x00,0x00,0x00,0x00,0x00,0x00,0x00,0x00,0x00,0x00,0x00,0x00,0x00,
0x00,0x00,0x00,0x00,0x00,0x00,0x00,0x00,0x00,0x00,0x00,0x00,0x00,0x00,0x00,0x00,
0x00,0x00,0x00,0x00,0x00,0x00,0x00,0x00,0x00,0x00,0x00,0x00,0x00,0x00,0x00,0x00,
0x00,0x00,0x00,0x00,0x00,0x00,0x00,0x00,0x00,0x00,0x00,0x00,0x00,0x00,0x00,0x00,
0x00,0x00,0x00,0x00,0x00,0x00,0x00,0x00,0x00,0x00,0x00,0x00,0x00,0x00,0x00,0x00,
0x00,0x00,0x00,0x00,0x00,0x00,0x00,0x00,0x00,0x00,0x00,0x00,0x00,0x00,0x00,0x00,
0x00,0x00,0x00,0x00,0x00,0x00,0x00,0x00,0x00,0x00,0x00,0x00,0x00,0x00,0x00,0x00,
0x00,0x00,0x00,0x00,0x00,0x00,0x00,0x00,0x00,0x00,0x00,0x00,0x00,0x00,0x00,0x00,
0x00,0x00,0x00,0x00,0x00,0x00,0x00,0x00,0x00,0x00,0x00,0x00,0x00,0x00,0x00,0x00,
0x00,0x00,0x00,0x00,0x00,0x00,0x00,0x00,0x00,0x00,0x00,0x00,0x00,0x00,0x00,0x00,
0x00,0x00,0x00,0x00,0x00,0x00,0x00,0x00,0x00,0x00,0x00,0x00,0x00,0x00,0x00,0x00,
0x00,0x00,0x00,0x00,0x00,0x00,0x00,0x00,0x00,0x00,0x00,0x00,0x00,0x00,0x00,0x00,
0x00,0x00,0x00,0x00,0x00,0x00,0x00,0x00,0x00,0x00,0x00,0x00,0x00,0x00,0x00,0x00,
0x00,0x00,0x00,0x00,0x00,0x00,0x00,0x00,0x00,0x00,0x00,0x00,0x00,0x00,0x00,0x00,
0x00,0x00,0x00,0x00,0x00,0x00,0x00,0x00,0x00,0x00,0x00,0x00,0x00,0x00,0x00,0x00,
0x00,0x00,0x00,0x00,0x00,0x00,0x00,0x00,0x00,0x00,0x00,0x00,0x00,0x00,0x00,0x00,
0x00,0x00,0x00,0x00,0x00,0x00,0x00,0x00,0x00,0x00,0x00,0x00,0x00,0x00,0x00,0x00,
0x00,0x00,0x00,0x00,0x00,0x00,0x00,0x00,0x00,0x00,0x00,0x00,0x00,0x00,0x00,0x00,
0x00,0x00,0x00,0x00,0x00,0x00,0x00,0x00,0x00,0x00,0x00,0x00,0x00,0x00,0x00,0x00,
0x00,0x00,0x00,0x00,0x00,0x00,0x00,0x00,0x00,0x00,0x00,0x00,0x00,0x00,0x00,0x00,
0x00,0x00,0x00,0x00,0x00,0x00,0x00,0x00,0x00,0x00,0x00,0x00,0x00,0x00,0x00,0x00,
};

/* USER CODE END PTD */

void SystemClock_Config(void);

int main(void)
{

  /* MCU Configuration--------------------------------------------------------*/

  /* Reset of all peripherals, Initializes the Flash interface and the Systick. */
  HAL_Init();

  /* Configure the system clock */
  SystemClock_Config();

  /* Initialize all configured peripherals */
  MX_GPIO_Init();
  MX_SPI1_Init();
  /* USER CODE BEGIN 2 */

  HAL_Delay(100);
   LCD_Init ();
  /* USER CODE END 2 */

  /* Infinite loop */
  /* USER CODE BEGIN WHILE */
  while (1)
  {
	test_display(0x55,0x55,0x55);
	HAL_Delay(1000);

	LCD_Clear();
	test_display(0x0f,0x0f,0x0f);
	HAL_Delay(1000);

	LCD_Clear();
	disp_240x160(BMP);
	HAL_Delay(1000);

	LCD_Clear();
	disp_240x160(BMP1);
	HAL_Delay(1000);
	//HAL_Delay (1000);

    /* USER CODE END WHILE */

  }
}

void SystemClock_Config(void)
{
  RCC_OscInitTypeDef RCC_OscInitStruct = {0};
  RCC_ClkInitTypeDef RCC_ClkInitStruct = {0};

  /** Initializes the RCC Oscillators according to the specified parameters
  * in the RCC_OscInitTypeDef structure.
  */
  RCC_OscInitStruct.OscillatorType = RCC_OSCILLATORTYPE_HSE;
  RCC_OscInitStruct.HSEState = RCC_HSE_ON;
  RCC_OscInitStruct.HSEPredivValue = RCC_HSE_PREDIV_DIV1;
  RCC_OscInitStruct.HSIState = RCC_HSI_ON;
  RCC_OscInitStruct.PLL.PLLState = RCC_PLL_ON;
  RCC_OscInitStruct.PLL.PLLSource = RCC_PLLSOURCE_HSE;
  RCC_OscInitStruct.PLL.PLLMUL = RCC_PLL_MUL9;
  if (HAL_RCC_OscConfig(&RCC_OscInitStruct) != HAL_OK)
  {
    Error_Handler();
  }

  /** Initializes the CPU, AHB and APB buses clocks
  */
  RCC_ClkInitStruct.ClockType = RCC_CLOCKTYPE_HCLK|RCC_CLOCKTYPE_SYSCLK
                              |RCC_CLOCKTYPE_PCLK1|RCC_CLOCKTYPE_PCLK2;
  RCC_ClkInitStruct.SYSCLKSource = RCC_SYSCLKSOURCE_PLLCLK;
  RCC_ClkInitStruct.AHBCLKDivider = RCC_SYSCLK_DIV1;
  RCC_ClkInitStruct.APB1CLKDivider = RCC_HCLK_DIV2;
  RCC_ClkInitStruct.APB2CLKDivider = RCC_HCLK_DIV1;

  if (HAL_RCC_ClockConfig(&RCC_ClkInitStruct, FLASH_LATENCY_2) != HAL_OK)
  {
    Error_Handler();
  }
}

void Error_Handler(void)
{
  __disable_irq();
  while (1)
  {
  }
}
